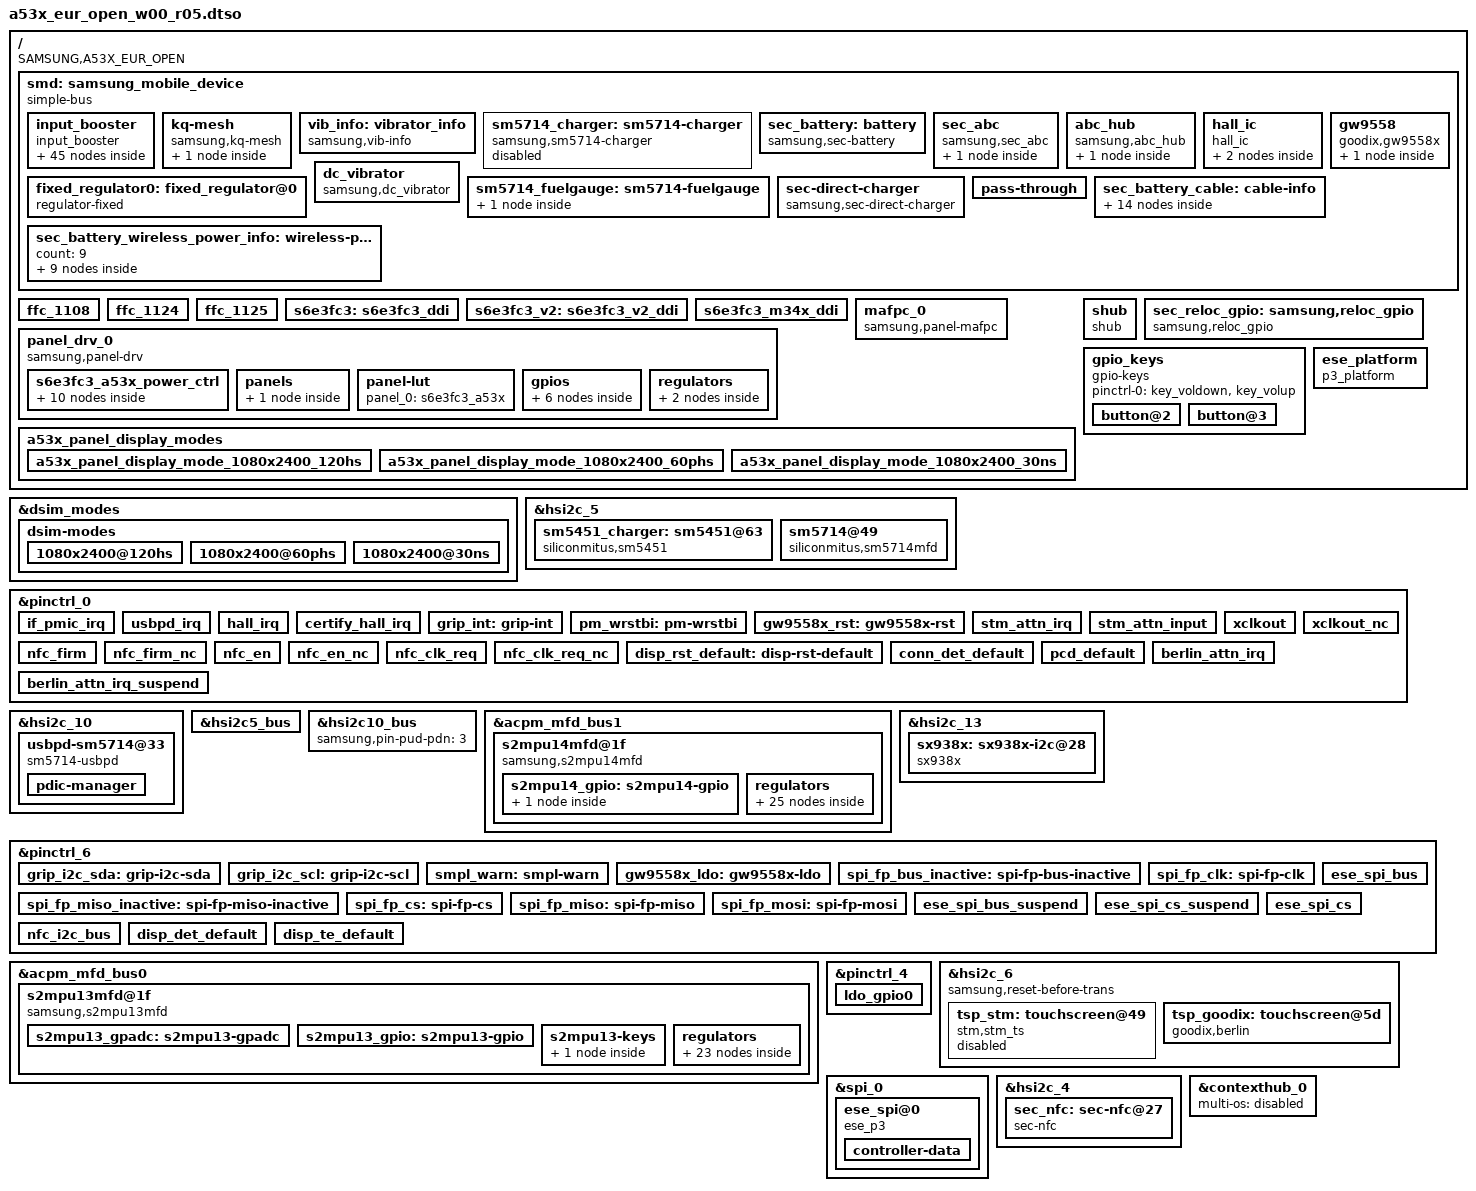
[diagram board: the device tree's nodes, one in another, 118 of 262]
/*
 * Copyright (c) 2018 Samsung Electronics Co., Ltd.
 *              http://www.samsung.com
 *
 * This program is free software; you can redistribute it and/or modify
 * it under the terms of the GNU General Public License version 2 as
 * published by the Free Software Foundation.
*/

/dts-v1/;
/plugin/;

#include <dt-bindings/battery/sec-battery.h>
#include <dt-bindings/clock/s5e8825.h>
#include <dt-bindings/camera/exynos_is_dt.h>
#include <dt-bindings/display/panel-display.h>
#include <dt-bindings/gpio/gpio.h>
#include <dt-bindings/interrupt-controller/s5e8825.h>
#include <dt-bindings/soc/samsung/exynos-cpif.h>
#include <dt-bindings/soc/samsung/exynos-dit.h>

/ {
	fragment@smd {
		target-path = "/";

		__overlay__ {

			smd: samsung_mobile_device {
				compatible = "simple-bus";

				/* #include "../common/input_booster_s5e8825_k66-1.dtsi" */
				/* From input_booster_s5e8825_k66.py */
				/*
				 * Samsung Mobile Input-Booster device tree
				 *
				 * Copyright (c) 2018 Samsung Electronics Co., Ltd.
				 *		http://www.samsung.com
				 *
				 * This program is free software; you can redistribute it and/or modify
				 * it under the terms of the GNU General Public License version 2 as
				 * published by the Free Software Foundation.
				 */
				input_booster {
					status = "okay";
					compatible = "input_booster";
					max_resource_count = "7";
					max_cluster_count = "3";
					#address-cells = <1>;
					#size-cells = <0>;
					/* Each Cpu Cluster Start Cpu */
					cpu_cluster_policy = "7,4,0";
					/* < CLUSTER2, CLUSTER1, CLUSTER0, MIF, INT, HMP, UCC> */
					ib_release_values = "0,0,0,0,0,0,0";
					/* Select Allowed Resource Index Group */
					allowed_resources = "1,3,4";

					booster_key@1 {
						input_booster,label = "key";
						input_booster,type = <0>;
						input_booster,head_time = <0x1f4>;
						input_booster,tail_time = <0>;

						inputbooster,resource {
							compatible = "resource";

							resource@1 {
								resource,label = "cluster1";
								resource,value = <0x177000 0>;
							};

							resource@4 {
								resource,label = "mif";
								resource,value = <0 0>;
							};

							resource@5 {
								resource,label = "int";
								resource,value = <0 0>;
							};
						};
					};

					booster_key@2 {
						input_booster,label = "touchkey";
						input_booster,type = <1>;
						input_booster,head_time = <0>;
						input_booster,tail_time = <0xc8>;

						inputbooster,resource {
							compatible = "resource";

							resource@1 {
								resource,label = "cluster1";
								resource,value = <0x177000 0>;
							};

							resource@4 {
								resource,label = "mif";
								resource,value = <0 0>;
							};

							resource@5 {
								resource,label = "int";
								resource,value = <0 0>;
							};
						};
					};

					booster_key@3 {
						input_booster,label = "touch";
						input_booster,type = <2>;
						input_booster,head_time = <0x82>;
						input_booster,tail_time = <0x1f4>;

						inputbooster,resource {
							compatible = "resource";

							resource@1 {
								resource,label = "cluster1";
								resource,value = <0x119400 0x101d00>;
							};

							resource@4 {
								resource,label = "mif";
								resource,value = <0xf78f0 0xf78f0>;
							};

							resource@5 {
								resource,label = "int";
								resource,value = <0 0>;
							};
						};
					};

					booster_key@4 {
						input_booster,label = "multitouch";
						input_booster,type = <3>;
						input_booster,head_time = <0x3e8>;
						input_booster,tail_time = <0x1f4>;

						inputbooster,resource {
							compatible = "resource";

							resource@1 {
								resource,label = "cluster1";
								resource,value = <0x119400 0x101d00>;
							};

							resource@4 {
								resource,label = "mif";
								resource,value = <0xf78f0 0xf78f0>;
							};

							resource@5 {
								resource,label = "int";
								resource,value = <0 0>;
							};
						};
					};

					booster_key@5 {
						input_booster,label = "keyboard";
						input_booster,type = <4>;
						input_booster,head_time = <0x82>;
						input_booster,tail_time = <0>;

						inputbooster,resource {
							compatible = "resource";

							resource@1 {
								resource,label = "cluster1";
								resource,value = <0x15f900 0x101d00>;
							};

							resource@4 {
								resource,label = "mif";
								resource,value = <0xf78f0 0xf78f0>;
							};

							resource@5 {
								resource,label = "int";
								resource,value = <0 0>;
							};
						};
					};

					booster_key@6 {
						input_booster,label = "mouse";
						input_booster,type = <5>;
						input_booster,head_time = <0x82>;
						input_booster,tail_time = <0x1f4>;

						inputbooster,resource {
							compatible = "resource";

							resource@1 {
								resource,label = "cluster1";
								resource,value = <0x15f900 0x101d00>;
							};

							resource@4 {
								resource,label = "mif";
								resource,value = <0xf78f0 0xf78f0>;
							};

							resource@5 {
								resource,label = "int";
								resource,value = <0 0>;
							};
						};
					};

					booster_key@7 {
						input_booster,label = "mouse_wheel";
						input_booster,type = <6>;
						input_booster,head_time = <0x82>;
						input_booster,tail_time = <0>;

						inputbooster,resource {
							compatible = "resource";

							resource@1 {
								resource,label = "cluster1";
								resource,value = <0x15f900 0>;
							};

							resource@4 {
								resource,label = "mif";
								resource,value = <0xf78f0 0>;
							};

							resource@5 {
								resource,label = "int";
								resource,value = <0 0>;
							};
						};
					};

					booster_key@8 {
						input_booster,label = "pen_hover";
						input_booster,type = <7>;
						input_booster,head_time = <0x82>;
						input_booster,tail_time = <0x1f4>;

						inputbooster,resource {
							compatible = "resource";

							resource@1 {
								resource,label = "cluster1";
								resource,value = <0x15f900 0x101d00>;
							};

							resource@4 {
								resource,label = "mif";
								resource,value = <0 0>;
							};

							resource@5 {
								resource,label = "int";
								resource,value = <0 0>;
							};
						};
					};

					booster_key@9 {
						input_booster,label = "pen";
						input_booster,type = <8>;
						input_booster,head_time = <0xc8>;
						input_booster,tail_time = <0x258>;

						inputbooster,resource {
							compatible = "resource";

							resource@1 {
								resource,label = "cluster1";
								resource,value = <0x1a5e00 0x119400>;
							};

							resource@4 {
								resource,label = "mif";
								resource,value = <0xf78f0 0xf78f0>;
							};

							resource@5 {
								resource,label = "int";
								resource,value = <0 0>;
							};
						};
					};
				};

				/* #include "../nc.dtsi" */
				/* From nc.py */
				/* #include "../kq_mesh.dtsi" */
				/* From kq_mesh.py */
				kq-mesh {
					compatible = "samsung,kq-mesh";
					status = "okay";

					features {
					};
				};

				/* #include "../vibrator_vib_info.dtsi" */
				/* From vibrator_vib_info.py */
				vib_info: vibrator_info {
					status = "okay";
					compatible = "samsung,vib-info";
					functions = "";
					samsung,intensities = <>;
					samsung,haptic_intensities = <>;
				};

				sm5714_charger: sm5714-charger {
					status = "disable";
					compatible = "samsung,sm5714-charger";
				};

				sec_battery: battery {
					battery,otg_name = "sm5714-otg";
					battery,fgsrc_switch_name = "sm5714-fuelgauge"; /* Fuelgauge voltage source */
					/* #include "../battery_common.dtsi" */
					/* From battery_common.py */
					status = "okay";
					compatible = "samsung,sec-battery";
					battery,vendor = "Battery";
					battery,charger_name = "sec-direct-charger";
					battery,fuelgauge_name = "sm5714-fuelgauge";
					battery,technology = <2>; /* POWER_SUPPLY_TECHNOLOGY_LION */
					battery,chip_vendor = "LSI";
					battery,batt_data_version = <1>;
					battery,adc_check_count = <5>;
					battery,temp_check_type = <SEC_BATTERY_TEMP_CHECK_TEMP>;
					battery,usb_temp_check_type = <0>;
					battery,chg_temp_check_type = <SEC_BATTERY_TEMP_CHECK_TEMP>;
					battery,wpc_temp_check_type = <SEC_BATTERY_TEMP_CHECK_NONE>;
					battery,lrp_temp_check_type = <0>;
					battery,thermal_source = <SEC_BATTERY_THERMAL_SOURCE_ADC>;
					battery,usb_thermal_source = <0>;
					battery,chg_thermal_source = <SEC_BATTERY_THERMAL_SOURCE_ADC>;
					battery,wpc_thermal_source = <SEC_BATTERY_THERMAL_SOURCE_NONE>; /* SEC_BATTERY_THERMAL_SOURCE_NONE */
					battery,inbat_ocv_type =  <SEC_BATTERY_OCV_NONE>;
					battery,polling_time = <10 30 30 30 3600>;
					battery,cable_check_type = <SEC_BATTERY_CABLE_CHECK_PSY>;
					battery,cable_source_type = <SEC_BATTERY_CABLE_SOURCE_EXTERNAL>;
					battery,polling_type = <SEC_BATTERY_MONITOR_ALARM>; /* SEC_BATTERY_MONITOR_ALARM */
					battery,monitor_initial_count = <0>;
					battery,battery_check_type = <0>; /* SEC_BATTERY_CHECK_NONE */
					battery,ovp_uvlo_check_type = <SEC_BATTERY_OVP_UVLO_CHGPOLLING>; /* SEC_BATTERY_OVP_UVLO_CHGPOLLING */
					battery,temp_check_count = <1>;
					battery,usb_protection_temp = <610>;
					battery,temp_gap_bat_usb = <200>;
					battery,overheatlimit_threshold = <700>;
					battery,overheatlimit_recovery = <680>;
					battery,wire_warm_overheat_thresh = <500>;
					battery,wire_normal_warm_thresh = <420>;
					battery,wire_cool1_normal_thresh = <180>;
					battery,wire_cool2_cool1_thresh = <150>;
					battery,wire_cool3_cool2_thresh = <50>;
					battery,wire_cold_cool3_thresh = <0>;
					battery,wireless_warm_overheat_thresh = <500>;
					battery,wireless_normal_warm_thresh = <420>;
					battery,wireless_cool1_normal_thresh = <180>;
					battery,wireless_cool2_cool1_thresh = <150>;
					battery,wireless_cool3_cool2_thresh = <50>;
					battery,wireless_cold_cool3_thresh = <0>;
					battery,tx_high_threshold = <500>;
					battery,tx_high_recovery = <450>;
					battery,tx_low_threshold = <0>;
					battery,tx_low_recovery = <50>;
					battery,wire_warm_current = <1735>; /* Less than or equal to 0.72C */
					/* DC 4390 AFC 3150 */
					battery,wire_cool1_current = <0xa8c>; /* Less than or equal to 0.72C */
					battery,wire_cool2_current = <1150>; /* 0.238C */
					battery,wire_cool3_current = <450>; /* 0.1C */
					battery,wireless_warm_current = <1048>; /* 0.24C */
					battery,wireless_cool1_current = <3146>; /* 0.72C */
					battery,wireless_cool2_current = <1048>; /* 0.24C */
					battery,wireless_cool3_current = <437>; /* 0.1C */
					battery,full_check_type = <SEC_BATTERY_FULLCHARGED_FG_CURRENT>;
					battery,full_check_type_2nd = <SEC_BATTERY_FULLCHARGED_FG_CURRENT>;
					battery,full_check_count = <1>;
					battery,chg_gpio_full_check = <0>;
					battery,chg_polarity_full_check = <1>;
					battery,chg_high_temp = <600>;
					battery,chg_high_temp_recovery = <560>;
					battery,chg_input_limit_current = <1000>;
					battery,chg_charging_limit_current = <1400>;
					/* 45w pwr on, 45w pwr off, 25w pwr on, 25w pwr off */
					battery,dchg_high_temp = <0x258>;
					battery,dchg_high_temp_recovery = <0x230>;
					battery,dchg_high_batt_temp = <0x190>; /* DISABLED */
					battery,dchg_high_batt_temp_recovery = <0x17c>; /* DISABLED */
					battery,dchg_input_limit_current = <1000>;
					battery,dchg_charging_limit_current = <2000>;
					battery,wpc_temp_control_source = <1>;
					battery,wpc_high_temp = <400>;
					battery,wpc_high_temp_recovery = <380>;
					battery,wpc_input_limit_current = <800>;
					battery,wpc_charging_limit_current = <1000>;
					battery,wpc_temp_lcd_on_control_source = <1>;
					battery,wpc_lcd_on_input_limit_current = <800>;
					battery,wpc_store_high_temp = <360>;
					battery,wpc_store_high_temp_recovery = <340>;
					battery,wpc_store_charging_limit_current = <400>;
					battery,wpc_store_lcd_on_high_temp = <360>;
					battery,wpc_store_lcd_on_high_temp_rec = <300>;
					battery,wpc_store_lcd_on_charging_limit_current = <400>;
					battery,fcc_by_tx = <1200>;
					battery,sleep_mode_limit_current = <800>;
					battery,wc_full_input_limit_current = <100>;
					battery,ta_alert_wa;
					battery,mix_high_temp = <420>;
					battery,mix_high_chg_temp = <500>;
					battery,mix_high_temp_recovery = <390>;
					/* battery,usb_conn_slope_avg = <9>; */
					/* battery,enable_mix_v2; */
					/* if you want to use mix_v2 concept, add "battery,enable_mix_v2;" */
					battery,mix_v2_lrp_recov = <460>;
					battery,mix_v2_lrp_cond = <480>;
					battery,mix_v2_bat_cond = <480>;
					battery,mix_v2_chg_cond = <0>; /* 0 means no use chg thm condition */
					battery,mix_v2_dchg_cond = <0>; /* 0 means no use dchg thm condition */
					battery,full_condition_type = <(SEC_BATTERY_FULL_CONDITION_NOTIMEFULL | SEC_BATTERY_FULL_CONDITION_VCELL)>;
					battery,full_condition_soc = <93>;
					/* battery,full_condition_vcell = FV - 50mV set when variable is parsed */
					battery,recharge_check_count = <1>;
					battery,recharge_condition_type = <SEC_BATTERY_RECHARGE_CONDITION_VCELL>;
					battery,recharge_condition_soc = <98>;
					/* battery,recharge_condition_vcell = FV - 70mV set when variable is parsed */
					battery,charging_reset_time = <0>;
					battery,chg_float_voltage = <0x1144>;
					battery,pre_afc_work_delay = <2000>;
					battery,pre_wc_afc_work_delay = <4000>;
					battery,pre_afc_input_current = <500>;
					battery,pre_wc_afc_input_current = <500>;
					battery,swelling_high_rechg_voltage = <4050>;
					/*battery,swelling_low_rechg_voltage = FV - 150mA set when variable is parsed */
					battery,siop_icl = <1200>;
					battery,siop_fcc = <1800>;
					battery,siop_hv_icl = <675>;
					battery,siop_hv_icl_2nd = <550>;
					battery,siop_hv_fcc = <1800>;
					battery,siop_apdo_icl = <1000>;
					battery,siop_apdo_fcc = <2000>;
					battery,siop_wpc_icl = <600>;
					battery,siop_wpc_fcc = <1000 500 100>; /* siop_level 70 10 0 */
					battery,siop_hv_wpc_icl = <700>;
					battery,siop_hv_wpc_fcc = <1000 500 100>; /* siop_level 70 10 0 */
					battery,siop_store_hv_wpc_icl = <450>;
					battery,store_mode_buckoff;
					/* trig, recov */
					battery,temp_table_LRP_45W = <385 365>;
					battery,rp_current_rp1 = <500>;
					battery,rp_current_rp2 = <1500>;
					battery,rp_current_rp3 = <3000>;
					battery,rp_current_rdu_rp3 = <2100>;
					battery,rp_current_abnormal_rp3 = <1800>;
					battery,pd_charging_charge_power = <15000>;
					battery,max_charging_current = <0xa8c>;
					battery,store_mode_charging_max = <70>;
					battery,store_mode_charging_min = <60>;
					battery,wireless_cc_cv = <85>;
					battery,wireless_otg_input_current = <900>;
					battery,age_data_cycle = <0 0x12c 0x190 0x2bc 0x3e8>;
					battery,age_data_full_condition_soc = <93 92 91 90 89>;
					battery,age_data_common_offset = <0 0x14 0x28 0x6e>;
					/* battery,age_data_max_charging_current_offset = <0 100 200 300 400>; */
					/* cycle, chg_float_voltage, recharge_condition_vcell, full_condition_vcell, full_condition_soc, step charging condition */
					battery,age_data = <0 0x1144 0x10fe 0x1112 0x5d 0x12c 0x1130 0x10ea 0x10fe 0x5c 0x190 0x111c 0x10d6 0x10ea 0x5b 0x2bc 0x1108 0x10c2 0x10d6 0x5a 0x3e8 0x10d6 0x1090 0x10a4 0x59>;
					battery,health_condition_cycle = <900 1200 1500>;
					battery,health_condition_asoc = <0 0 0>; /* Default ASOC Disabled */
					battery,max_input_voltage = <9000>; /* mV */
					battery,max_input_current = <3000>; /* mA */
					battery,cisd_alg_index = <8>;
					battery,cisd_max_voltage_thr = <5000>; /* batttery ovp dettection voltage */
					battery,ignore_cisd_index = <0 0>;
					battery,ignore_cisd_index_d = <0 80>; /* Do not use BUCK_OFF_PER_DAY, DROP_SENSOR_PER_DAY */
					battery,expired_time = <9900>; /* 95 + 60 minutes = 155 */
					battery,recharging_expired_time = <5400>; /* 90 minutes */
					battery,battery_full_capacity = <5000>;
					battery,ttf_capacity = <4390>;
					battery,cv_data = <0xd27 0x352 0x690 0xbed 0x35c 0x5ef 0xaf2 0x366 0x5bc 0x9ca 0x370 0x576 0x844 0x37a 0x52f 0x816 0x384 0x4d4 0x735 0x38e 0x470 0x727 0x398 0x40b 0x704 0x3a2 0x39c 0x68c 0x3ac 0x33e 0x5f9 0x3b6 0x2c5 0x566 0x3c0 0x24c 0x410 0x3ca 0x1d4 0x3bd 0x3d4 0x120 0x340 0x3de 0x6b 0x2c9 0x3e8 0>;
					io-channels = <&s2mpu13_gpadc 2 &s2mpu13_gpadc 3>;
					io-channel-names = "adc-temp", "adc-chg-temp", "n/a", "n/a", "n/a";
					/* /home/dpi/qb5_8814/workspace/P4_1716/kernel/kmodule/battery/suwon/common/dts/a26xs/battery_common.dtsi */
					pinctrl-names = "default";
					battery,dchg_temp_check_type = <SEC_BATTERY_TEMP_CHECK_TEMP>;
					battery,dchg_thermal_source = <SEC_BATTERY_THERMAL_SOURCE_ADC>;
					battery,dctp_by_cgtp;
					battery,temp_table_adc = <0x133 0x168 0x1a5 0x1f8 0x23e 0x29e 0x2f9 0x37c 0x418 0x4c0 0x575 0x652 0x714 0x7f3 0x8d8 0x9b9 0xa9a 0xb6c 0xc32 0xce1 0xd85 0xe0d 0xe83>;
					battery,temp_table_data = <
						900 850 800 750 700 650 600 550 500 450
						400 350 300 250 200 150 100 50 0 (-50)
						(-100) (-150) (-200)
						>;
					battery,chg_temp_table_adc = <0x125 0x15d 0x198 0x1e6 0x22d 0x28d 0x2d7 0x360 0x3ff 0x49c 0x558 0x623 0x6e6 0x78e 0x8b4 0x975 0xa4b 0xac2 0xbd3 0xc7f 0xd4f 0xdee 0xe65>;
					battery,chg_temp_table_data = <
						900 850 800 750 700 650 600 550 500 450
						400 350 300 250 200 150 100 50 0 (-50)
						(-100) (-150) (-200)
						>;
					battery,full_condition_vcell = <0x1112>;
					battery,recharge_condition_vcell = <0x10fe>;
					battery,high_temp_float = <4200>;
					battery,low_temp_float = <0x1144>;
					battery,swelling_low_rechg_voltage = <0x10ae>;
					battery,chg_ocp_current = <0>;
					battery,max_charging_charge_power = <25000>; /* 25W */
					/* step charging option */
					battery,step_chg_type = <0>;
					/* direct step charging option */
					battery,dc_step_chg_type = <0xE9>;
					battery,dc_step_chg_charge_power = <22000>;
					battery,dc_step_chg_step = <3>;
					battery,dc_step_chg_cond_vol = <0xfd2 0x109a 0x1144>; /*<25w 3step> STEP_CHARGING_CONDITION_VOLTAGE */
					battery,dc_step_chg_val_vfloat = <0xfd2 0x109a 0x1144>; /* <25w 3step> STEP_CHARGING_CONDITION_FLOAT_VOLTAGE */
					battery,dc_step_chg_val_iout = <0x12c0 0xfd2 0xe10>; /* <25w 3step> */
					battery,dc_step_chg_iin_check_cnt = <3>;
					battery,dc_step_chg_cond_soc = <0x19 0x41 0x64>; /* <25w 3step> STEP_CHARGING_CONDITION_SOC */
					battery,standard_curr = <0xe10>;
					battery,ttf_hv_charge_current = <2450>;
					battery,ttf_dc25_charge_current = <3800>;
					battery,support_vpdo;
					battery,d2d_check_type = <2>;
				};

				/* #include "../abc_spec_manager_type1.dtsi" */
				/* From abc_spec_manager_type1.py */
				sec_abc {
					compatible = "samsung,sec_abc";
					status = "okay";

					abc_spec_type1 {
						module_list = "gpu", "gpu_qc", "gpu_qc", "camera", "camera", "vib";
						name_list = "gpu_fault", "gpu_fault", "gpu_page_fault", "mipi_overflow", "i2c_fail", "int_gnd_short";
						threshold_cnt = <20>, <2>, <20>, <1>, <1>, <25>;
						threshold_time = <1200>, <1200>, <1200>, <0>, <0>, <5>;
					};
				};

				/* #include "../ap_slsi_s5e8825.dtsi" */
				/* From ap_slsi_s5e8825.py */
				/* #include "../abc_common.dtsi" */
				/* From abc_common.py */
				abc_hub {
					compatible = "samsung,abc_hub";
					status = "okay";

					bootc {
						bootc,time_spec_user = <100000>; /* user binary user build */
						bootc,time_spec_eng = <150000>; /* user binary eng build */
						bootc,time_spec_fac = <100000>; /* factory binary */
					};
				};

				hall_ic: hall_ic {
					status = "okay";
					compatible = "hall_ic";
					pinctrl-names = "default";
					pinctrl-0 = <&hall_irq &certify_hall_irq>;
					hall_ic,debounce-interval = <0x32>;

					hall: hall {
						event = <0x15>;
						gpios = <&gpa0 1 1>;
					};

					certify_hall: certify_hall {
						event = <0x1b>;
						gpios = <&gpa0 0 1>;
					};
				};

				gw9558 {
					compatible = "goodix,gw9558x";
					reg = <0>;
					spi-max-frequency = <0x17d7840>;
					clocks = <&clock 0x4c3 &clock 0x4d5>;
					clock-names = "gate_spi_clk", "ipclk_spi";
					pinctrl-names = "default", "pins_poweron", "pins_poweroff";
					pinctrl-0 = <&gw9558x_ldo &gw9558x_rst>;
					pinctrl-1 = <&spi_fp_clk &spi_fp_cs &spi_fp_miso &spi_fp_mosi>;
					pinctrl-2 = <&spi_fp_bus_inactive &spi_fp_miso_inactive>;
					gpio-controller;
					#gpio-cells = <2>;
					goodix,gpio_pwr = <&gpp3 4 0>;
					goodix,gpio_reset = <&gpc3 0 0>;
					goodix,chip_id = "GW9558";
					goodix,position = "11.81,0.00,9.10,9.10,14.80,14.80,12.00,12.00,5.00";
					goodix,modelinfo = "A536";
					goodix,rb = "800,235,-1,D8D8D8,8C8C8C";

					controller-data {
						cs-gpio = <&gpp0 7 0>;
						samsung,spi-feedback-delay = <0>;
						samsung,spi-chip-select-mode = <0>;
					};
				};

				fixed_regulator0: fixed_regulator@0 {
					compatible = "regulator-fixed";
					regulator-name = "fixed_regulator0";
					gpio = <&gpf1 0 0>;
					pinctrl-names = "default";
					pinctrl-0 = <&ldo_gpio0>;
					enable-active-high;
				};

				/* #include "../dc_vibrator.dtsi" */
				/* From dc_vibrator.py */
				dc_vibrator {
					compatible = "samsung,dc_vibrator";
					status = "okay";
					dc_vib,motor_type = "COINDC";
					dc_vib,regulator_name = "dc_vib";
					dc_vib-supply = <&s_l21_reg>;
				};

				/*
				 * sm5714 battery device tree common
				 *
				 * Copyright (c) 2021 Samsung Electronics Co., Ltd.
				 *		http://www.samsung.com
				 *
				 * This program is free software; you can redistribute it and/or modify
				 * it under the terms of the GNU General Public License version 2 as
				 * published by the Free Software Foundation.
				 */
				sm5714_fuelgauge: sm5714-fuelgauge {
					/* /home/dpi/qb5_8814/workspace/P4_1716/android/kernel/kmodule/battery/suwon/fuelgauge/sm5714/sm5714_fuelgauge.a53x.dtsi */
					/*
					 * A53x battery device tree common
					 *
					 * Copyright (c) 2021 Samsung Electronics Co., Ltd.
					 *		http://www.samsung.com
					 *
					 * This program is free software; you can redistribute it and/or modify
					 * it under the terms of the GNU General Public License version 2 as
					 * published by the Free Software Foundation.
					 */
					status = "okay";
					fuelgauge,fuel_alert_soc = <1>;
					fuelgauge,capacity_max = <1000>;
					fuelgauge,capacity_max_margin = <300>;
					fuelgauge,capacity_min = <0>;
					fuelgauge,capacity_calculation_type = <0x1F>;
					fuelgauge,using_temp_compensation;
					fuelgauge,low_temp_limit = <100>;
					fuelgauge,using_hw_vempty;
					fuelgauge,sw_v_empty_voltage = <3200>;
					fuelgauge,sw_v_empty_voltage_cisd = <3100>;
					fuelgauge,sw_v_empty_recover_voltage = <3480>;
					fuelgauge,capacity = <5000>;
					fuelgauge,bat_id_gpio = <
					&s2mpu14_gpio 8 0 /* BAT_ID_2 */
					&s2mpu14_gpio 7 0 /* BAT_ID_1 */
					>;

					battery_params {
						battery,id = <3>; /* default ID */
						/*
						 * BAT_ID_1/BAT_ID_2
						 * 11: ATL, 10: LGES
						 * 01: SDI, 00: BYD(TBD)
						 */
						/* 11 : ATL battery data */
						battery3,battery_type = <4420 0x2501>; /* batt_v_max, cap */
						battery3,battery_table0 = <
							0x1400 0x1B3F 0x1C19 0x1CE4 0x1D61 0x1D7B 0x1D89 0x1D93
							0x1DBE 0x1DEE 0x1E42 0x1E5E 0x1E8D 0x1EB7 0x1F0E 0x1F40
							0x1F8D 0x200B 0x206A 0x20D4 0x2146 0x21FD 0x2305 0x2400
							>;
						battery3,battery_table1 = <
							0x0000 0x0099 0x0199 0x0319 0x0499 0x0599 0x0799 0x0B33
							0x0E33 0x1233 0x1C4C 0x2166 0x28E6 0x2E00 0x3599 0x3819
							0x3A99 0x4233 0x4733 0x4C4C 0x514C 0x58E6 0x6400 0x6419
							>;
						battery3,battery_table2 = <
							0x444B 0x3E40 0x3B3C 0x3738 0x3435 0x3334 0x3333 0x3233
							0x444B 0x3E40 0x3B3C 0x3738 0x3435 0x3334 0x3333 0x3233
							>;
						/*spare min max factor chg_factor dischg_factor manvalue*/
						battery3,rs_value = <0x48 0x48 0x3800 0x10A 0x599 0x599 0x50>;
						battery3,v_alarm = <3100 200>;
						battery3,topoff = <750>;
						battery3,i_cal = <1 0x0 0x0800 0x0800 0 0x0 0x0800 0x0825>;
						battery3,v_cal = <1 0 0 0 0 0x18 0>;
						battery3,temp_std = <25>;
						battery3,tem_poff = <3400 50 3250 50>;
						battery3,aux_ctrl = <0x322 0x5800>;
						battery3,data_ver = <4>;
						battery3,v_max_table = <0x2305 0x22DF 0x22B8 0x2290 0x222F>;
						battery3,q_max_table = <0x2501 0x2463 0x23C4 0x2326 0x219A>;
						/* 01 : SDI battery data */
						battery1,battery_type = <4420 0x24ED>; /* batt_v_max, cap */
						battery1,battery_table0 = <
							0x1400 0x1B41 0x1C27 0x1CD8 0x1D30 0x1D6B 0x1D7B 0x1D8E
							0x1DE3 0x1E0B 0x1E51 0x1E70 0x1EAA 0x1EDD 0x1F1E 0x1F4C
							0x1F97 0x1FFD 0x205F 0x20C8 0x213B 0x21F2 0x22FA 0x2400
							>;
						battery1,battery_table1 = <
							0x0000 0x0080 0x0199 0x0319 0x0433 0x0533 0x064C 0x0B80
							0x1233 0x1766 0x1F4C 0x2480 0x2C4C 0x3180 0x36B3 0x394C
							0x3BE6 0x4119 0x464C 0x4B80 0x50B3 0x5880 0x6400 0x6419
							>;
						battery1,battery_table2 = <
							0x444B 0x3E40 0x3B3C 0x3738 0x3435 0x3334 0x3333 0x3233
							0x444B 0x3E40 0x3B3C 0x3738 0x3435 0x3334 0x3333 0x3233
							>;
						/*spare min max factor chg_factor dischg_factor manvalue*/
						battery1,rs_value = <0x48 0x48 0x3800 0x10A 0x599 0x599 0x50>;
						battery1,v_alarm = <3100 200>;
						battery1,topoff = <750>;
						battery1,i_cal = <1 0x0 0x0800 0x0800 0 0x0 0x0800 0x0825>;
						battery1,v_cal = <1 0 0 0 0 0x18 0>;
						battery1,temp_std = <25>;
						battery1,tem_poff = <3400 50 3250 50>;
						battery1,aux_ctrl = <0x322 0x5800>;
						battery1,data_ver = <2>;
						battery1,v_max_table = <0x22FA 0x22D4 0x22AD 0x2286 0x2225>;
						battery1,q_max_table = <0x24ED 0x2449 0x23A3 0x22FF 0x2163>;
						/* 02 : LGES battery data */
						battery2,battery_type = <4420 0x23FD>; /* batt_v_max, cap */
						battery2,battery_table0 = <
							0x1400 0x1B56 0x1C21 0x1D02 0x1D48 0x1D73 0x1D8A 0x1D92
							0x1DB7 0x1DF2 0x1E4D 0x1E6C 0x1EA5 0x1ED6 0x1F14 0x1F47
							0x1F8D 0x1FD5 0x2030 0x20D5 0x2151 0x21D4 0x22E7 0x2400
							>;
						battery2,battery_table1 = <
							0x0000 0x0099 0x01B3 0x03CC 0x04E6 0x0600 0x09CC 0x0C80
							0x0F33 0x1499 0x1F66 0x24CC 0x2CE6 0x324C 0x37B3 0x3A66
							0x3D19 0x3FCC 0x4533 0x4D4C 0x52B3 0x5819 0x6400 0x6419
							>;
						battery2,battery_table2 = <
							0x444B 0x3E40 0x3B3C 0x3738 0x3435 0x3334 0x3333 0x3233
							0x444B 0x3E40 0x3B3C 0x3738 0x3435 0x3334 0x3333 0x3233
							>;
						/*spare min max factor chg_factor dischg_factor manvalue*/
						battery2,rs_value = <0x48 0x48 0x3800 0x10A 0x599 0x599 0x50>;
						battery2,v_alarm = <3100 200>;
						battery2,topoff = <750>;
						battery2,i_cal = <1 0x0 0x0800 0x0800 0 0x0  0x0808 0x0825>;
						battery2,v_cal = <1 0 0 1 0 0 0>;
						battery2,temp_std = <25>;
						battery2,tem_poff = <3400 50 3250 50>;
						battery2,aux_ctrl = <0x322 0x5800>;
						battery2,data_ver = <2>;
						battery2,v_max_table = <0x22E7 0x22C0 0x229A 0x2274 0x2214>;
						battery2,q_max_table = <0x23FD 0x2344 0x228C 0x21D4 0x2063>;
						/* 00 : BYD battery data */
						battery0,battery_type = <4420 0x24B3>; /* batt_v_max, cap */
						battery0,battery_table0 = <
							0x1400 0x1B21 0x1BFE 0x1CCD 0x1D51 0x1D79 0x1D86 0x1D96
							0x1DBB 0x1DF4 0x1E06 0x1E4E 0x1E93 0x1EF8 0x1F40 0x1F77
							0x1FC6 0x1FF9 0x205C 0x20C8 0x213E 0x21FB 0x2306 0x2400
							>;
						battery0,battery_table1 = <
							0x0000 0x0080 0x0180 0x0319 0x04B3 0x05B3 0x074C 0x0C19
							0x0EB3 0x1400 0x1699 0x1E80 0x2900 0x3399 0x38CC 0x3B80
							0x3E19 0x40B3 0x4600 0x4B4C 0x5080 0x5866 0x6400 0x6419
							>;
						battery0,battery_table2 = <
							0x444B 0x3E40 0x3B3C 0x3738 0x3435 0x3334 0x3333 0x3233
							0x444B 0x3E40 0x3B3C 0x3738 0x3435 0x3334 0x3333 0x3233
							>;
						/*spare min max factor chg_factor dischg_factor manvalue*/
						battery0,rs_value = <0x48 0x48 0x3800 0x10A 0x599 0x599 0x50>;
						battery0,v_alarm = <3100 200>;
						battery0,topoff = <750>;
						battery0,i_cal = <1 0x0 0x0800 0x0800 0 0x0  0x0800 0x0825>;
						battery0,v_cal = <1 0 0 0 0 0x18 0>;
						battery0,temp_std = <25>;
						battery0,tem_poff = <3400 50 3250 50>;
						battery0,aux_ctrl = <0x322 0x5800>;
						battery0,data_ver = <2>;
						battery0,v_max_table = <0x2306 0x22DE 0x22B7 0x228F 0x222C>;
						battery0,q_max_table = <0x24B3 0x240E 0x2369 0x2326 0x212A>;
					};
				};

				/* #include "../sec_direct_charger.dtsi" */
				/* From sec_direct_charger.py */
				sec-direct-charger {
					status = "okay";
					compatible = "samsung,sec-direct-charger";
					charger,battery_name = "battery";
					charger,main_charger = "sm5714-charger";
					charger,direct_charger = "sm5451-charger";
					charger,dchg_min_current = <2000>;
					charger,ta_alert_wa;
				};

				/* /home/dpi/qb5_8814/workspace/P4_1716/kernel/kmodule/battery/suwon/common/sec_direct_charger/dts/a26xs/sec_direct_charger.dtsi */
				pass-through {
					start_delay = <5000>; /* msec */
					init_delay = <5000>; /* msec */
					min_cap = <200>; /* 0.1 % */
					fixed_sc_cap = <900>; /* 0.1 % */
					max_icl = <3000>; /* mA */
					vfloat = <0x1144>;
				};

				/* sec_battery_cable
				 *   0	UNKNOWN,
				 *   1	NONE,
				 *   2	PREPARE_TA,
				 *   3	TA,
				 *   4	USB,
				 *   5	USB_CDP,
				 *   6	9V_TA,
				 *   7	9V_ERR,
				 *   8	9V_UNKNOWN,
				 *   9	12V_TA,
				 *  10	WIRELESS,
				 *  11	HV_WIRELESS,
				 *  12	PMA_WIRELESS,
				 *  13	WIRELESS_PACK,
				 *  14	CABLE_WIRELESS_HV_PACK,
				 *  15	WIRELESS_STAND,
				 *  16	WIRELESS_HV_STAND,
				 *  17	QC20,
				 *  18	QC30,
				 *  19	PDIC,
				 *  20	UARTOFF,
				 *  21	OTG,
				 *  22	LAN_HUB,
				 *  23	POWER_SHARING,
				 *  24	HMT_CONNECTED,
				 *  25	HMT_CHARGE,
				 *  26	HV_TA_CHG_LIMIT,
				 *  27	WIRELESS_VEHICLE,
				 *  28	WIRELESS_HV_VEHICLE,
				 *  29	PREPARE_WIRELESS_HV,
				 *  30  TIMEOUT,
				 *  31  SMART_OTG,
				 *  32  SMART_NOTG,
				 *  33  WIRELESS_TX,
				 *  34	HV_WIRELESS_20,
				 *  35	HV_WIRELESS_20_LIMIT,
				 *  36	WIRELESS_FAKE,
				 *  37  PREPARE_WIRELESS_20,
				 *  38	CABLE_PDIC_APDO,
				 *  39  CABLE_POGO,
				 *  40  CABLE_POGO_9V,
				 *  41  FPDO_DC,
				 *  42	CABLE_MAX,
				 */
				sec_battery_cable: cable-info {
					default_input_current = <1800>;
					default_charging_current = <2100>;
					full_check_current_1st = <750>;
					full_check_current_2nd = <250>;

					current_group_1 {
						cable_number = <
							SEC_BATTERY_CABLE_PREPARE_TA
							SEC_BATTERY_CABLE_PDIC
							SEC_BATTERY_CABLE_OTG
							SEC_BATTERY_CABLE_LAN_HUB
							SEC_BATTERY_CABLE_POWER_SHARING>;
						input_current = <500>;
						charging_current = <500>;
					};

					current_group_2 {
						cable_number = <
							SEC_BATTERY_CABLE_HMT_CHARGE
							SEC_BATTERY_CABLE_SMART_OTG>;
						input_current = <1000>;
						charging_current = <1000>;
					};

					current_group_3 {
						cable_number = <
							SEC_BATTERY_CABLE_USB_CDP
							SEC_BATTERY_CABLE_SMART_NOTG>;
						input_current = <1500>;
						charging_current = <1500>;
					};

					current_group_4 {
						cable_number = <SEC_BATTERY_CABLE_9V_TA SEC_BATTERY_CABLE_9V_ERR
							SEC_BATTERY_CABLE_9V_UNKNOWN SEC_BATTERY_CABLE_QC20 SEC_BATTERY_CABLE_QC30>;
						input_current = <1650>;
						/*
						 * cable_number = <SEC_BATTERY_CABLE_9V_TA SEC_BATTERY_CABLE_9V_ERR
						 * SEC_BATTERY_CABLE_9V_UNKNOWN SEC_BATTERY_CABLE_QC20 SEC_BATTERY_CABLE_QC30>;
						 */
						charging_current = <0xa8c>;
					};

					current_group_5 {
						cable_number = <SEC_BATTERY_CABLE_12V_TA>;
						input_current = <1650>;
						/* cable_number = <SEC_BATTERY_CABLE_12V_TA>; */
						charging_current = <0xa8c>;
					};

					current_group_6 {
						cable_number = <
							SEC_BATTERY_CABLE_WIRELESS
							SEC_BATTERY_CABLE_PMA_WIRELESS
							SEC_BATTERY_CABLE_WIRELESS_STAND
							SEC_BATTERY_CABLE_WIRELESS_VEHICLE
							SEC_BATTERY_CABLE_WIRELESS_FAKE>;
						input_current = <800>;
						charging_current = <2350>;
					};

					current_group_7 {
						cable_number = <SEC_BATTERY_CABLE_WIRELESS_PACK>;
						input_current = <700>;
						charging_current = <2350>;
					};

					current_group_8 {
						cable_number = <SEC_BATTERY_CABLE_HMT_CONNECTED>;
						input_current = <1000>;
						charging_current = <450>;
					};

					current_group_9 {
						cable_number = <SEC_BATTERY_CABLE_HV_TA_CHG_LIMIT>;
						input_current = <1800>;
						charging_current = <1800>;
					};

					current_group_10 {
						cable_number = <
							SEC_BATTERY_CABLE_HV_WIRELESS
							SEC_BATTERY_CABLE_WIRELESS_HV_PACK
							SEC_BATTERY_CABLE_WIRELESS_HV_STAND
							SEC_BATTERY_CABLE_WIRELESS_HV_VEHICLE
							SEC_BATTERY_CABLE_HV_WIRELESS_20_LIMIT>;
						input_current = <650>;
						charging_current = <2350>;
					};

					current_group_11 {
						cable_number = <
							SEC_BATTERY_CABLE_PREPARE_WIRELESS_HV
							SEC_BATTERY_CABLE_PREPARE_WIRELESS_20>;
						input_current = <500>;
						charging_current = <1200>;
					};

					current_group_12 {
						cable_number = <
							SEC_BATTERY_CABLE_NONE
							SEC_BATTERY_CABLE_USB
							SEC_BATTERY_CABLE_TIMEOUT>;
						input_current = <475>;
						charging_current = <550>;
					};

					current_group_13 {
						cable_number = <SEC_BATTERY_CABLE_HV_WIRELESS_20>;
						input_current = <1200>;
						charging_current = <2350>;
					};

					current_group_14 {
						cable_number = <SEC_BATTERY_CABLE_WIRELESS_TX>;
						input_current = <800>;
						charging_current = <2350>;
					};
				};

				sec_battery_wireless_power_info: wireless-power-info {
					count = <9>;

					current_group_0 {
						wireless_power_class = <2>;
						vout = <9000>;
						input_current_limit = <830>;
						fast_charging_current = <3150>;
						ttf_charge_current = <1500>;
						rx_power = <7500>;
					};

					current_group_1 {
						wireless_power_class = <2>;
						vout = <10000>;
						input_current_limit = <750>;
						fast_charging_current = <3150>;
						ttf_charge_current = <1500>;
						rx_power = <7500>;
					};

					current_group_2 {
						wireless_power_class = <2>;
						vout = <11000>;
						input_current_limit = <680>;
						fast_charging_current = <3150>;
						ttf_charge_current = <1500>;
						rx_power = <7500>;
					};

					current_group_3 {
						wireless_power_class = <2>;
						vout = <12000>;
						input_current_limit = <625>;
						fast_charging_current = <3150>;
						ttf_charge_current = <1500>;
						rx_power = <7500>;
					};

					current_group_4 {
						wireless_power_class = <2>;
						vout = <9000>;
						input_current_limit = <1330>;
						fast_charging_current = <3150>;
						ttf_charge_current = <2175>;
						rx_power = <12000>;
					};

					current_group_5 {
						wireless_power_class = <2>;
						vout = <11000>;
						input_current_limit = <1090>;
						fast_charging_current = <3150>;
						ttf_charge_current = <2100>;
						rx_power = <12000>;
					};

					current_group_6 {
						wireless_power_class = <2>;
						vout = <12000>;
						input_current_limit = <1000>;
						fast_charging_current = <3150>;
						ttf_charge_current = <2100>;
						rx_power = <12000>;
					};

					current_group_7 {
						wireless_power_class = <2>;
						vout = <11000>;
						input_current_limit = <1360>;
						fast_charging_current = <3150>;
						ttf_charge_current = <2300>;
						rx_power = <15000>;
					};

					current_group_8 {
						wireless_power_class = <2>;
						vout = <12000>;
						input_current_limit = <1250>;
						fast_charging_current = <3150>;
						ttf_charge_current = <2300>;
						rx_power = <15000>;
					};
				};
			};
		};
	};
};

#include "../display_s6e3fc3_a53x_adaptive_mipi.dtsi"

/ {
	fragment@panel_drv {
		target-path = "/";

		__overlay__ {

			ffc_1108: ffc_1108 {
				osc = <0x2c434>;
				hs-clk = <0x454>;
				command = [c5 0d 10 80 45 53 c7];
			};

			ffc_1124: ffc_1124 {
				osc = <0x2c434>;
				hs-clk = <0x464>;
				command = [c5 0d 10 80 45 52 96];
			};

			ffc_1125: ffc_1125 {
				osc = <0x2c434>;
				hs-clk = <0x465>;
				command = [c5 0d 10 80 45 52 83];
			};

			s6e3fc3: s6e3fc3_ddi {
				id = <0x1083>;
				mode = <2>;
				resolution = <0x438 0x960>;
				size = <0x43 0x96>;
				timing,refresh = <0x3c>;
				timing,h-porch = <2 2 2>;
				timing,v-porch = <0xf 8 1>;
				timing,dsi-hs-clk = <0x454>;
				timing,pmsk = <2 0xaa 2 0x7627 0xd 4 0 0 0 0 0 0 0 0>;
				timing,dsi-escape-clk = <0x14>;
				mic_en = <0>;
				mic_ratio = <2>;
				mic_ver = <2>;
				type_of_ddi = <0>;
				dsc_en = <1>;
				dsc_cnt = <1>;
				dsc_slice_num = <2>;
				dsc_slice_h = <0x28>;
				data_lane = <4>;
				cmd_underrun_cnt = <0x26cf>;
				mres_en = <1>;
				mres_number = <1>;
				mres_width = <0x438>;
				mres_height = <0x960>;
				mres_dsc_width = <0x21c>;
				mres_dsc_height = <0x28>;
				mres_dsc_en = <1>;
				default_mode = <1>;
				display_mode = <0x438 0x960 0x78 0x83b 1 0x21c 0x28 0x438 0x960 0x3c 0x1f37 1 0x21c 0x28>;
				hdr_num = <0>;
				color_mode = <0 7 9>;
				dynamic_mipi_tbl = <&dsim_freq_1108 &dsim_freq_1124 &dsim_freq_1125>;
				dynamic_mipi_ffc0 = <&ffc_1108 &ffc_1124 &ffc_1125>;
			};

			s6e3fc3_v2: s6e3fc3_v2_ddi {
				id = <0x800004>;
				mode = <2>;
				resolution = <0x438 0x960>;
				size = <0x46 0x9b>;
				timing,refresh = <0x3c>;
				timing,h-porch = <2 2 2>;
				timing,v-porch = <0xf 8 1>;
				timing,dsi-hs-clk = <0x67c>;
				timing,pmsk = <4 0xff 1 0 0xd 4 0 0 0 0 0 0 0 0>;
				timing,dsi-escape-clk = <0x14>;
				mic_en = <0>;
				mic_ratio = <0>;
				mic_ver = <0>;
				type_of_ddi = <0>;
				dsc_en = <1>;
				dsc_cnt = <1>;
				dsc_slice_num = <2>;
				dsc_slice_h = <0x28>;
				data_lane = <4>;
				cmd_underrun_cnt = <0x26cf>;
				mres_en = <1>;
				mres_number = <1>;
				mres_width = <0x438>;
				mres_height = <0x960>;
				mres_dsc_width = <0x21c>;
				mres_dsc_height = <0x28>;
				mres_dsc_en = <1>;
				default_mode = <1>;
				display_mode = <0x438 0x960 0x5a 0x13e5 1 0x21c 0x28 0x438 0x960 0x3c 0x26cf 1 0x21c 0x28>;
				hdr_num = <0>;
			};

			s6e3fc3_m34x_ddi: s6e3fc3_m34x_ddi {
				size = <0x46 0x95>;
				hdr_num = <0>;
			};

			mafpc_0: mafpc_0 {
				compatible = "samsung,panel-mafpc";
				status = "okay";
			};

			panel_drv_0: panel_drv_0 {
				status = "okay";
				compatible = "samsung,panel-drv";
				panel,id = <0>;
				pinctrl-names = "default";
				pinctrl-0 = <&disp_rst_default &disp_det_default &conn_det_default &disp_te_default>;

				s6e3fc3_a53x_power_ctrl: s6e3fc3_a53x_power_ctrl {

					actions {

						fc3_a53x_vci_on: vci-on {
							type = <3>;
							reg = <&ddi_vci>;
						};

						fc3_a53x_vdd3_on: vdd3-on {
							type = <3>;
							reg = <&ddi_vdd3>;
						};

						fc3_a53x_vci_off: vci-off {
							type = <4>;
							reg = <&ddi_vci>;
						};

						fc3_a53x_vdd3_off: vdd3-off {
							type = <4>;
							reg = <&ddi_vdd3>;
						};

						fc3_a53x_delay_1ms: delay-1ms {
							type = <1>;
							value = <1>;
						};

						fc3_a53x_delay_10ms: delay-10ms {
							type = <1>;
							value = <10>;
						};

						fc3_a53x_reset_high: reset-high {
							type = <7>;
							gpio = <&disp_reset>;
						};

						fc3_a53x_reset_low: reset-low {
							type = <8>;
							gpio = <&disp_reset>;
						};
					};

					sequences {
						panel_boot_on = <&fc3_a53x_vci_on &fc3_a53x_vdd3_on>;
						panel_power_on = <
							&fc3_a53x_vci_on &fc3_a53x_vdd3_on
							&fc3_a53x_delay_10ms
							&fc3_a53x_reset_high &fc3_a53x_delay_10ms
						>;
						panel_power_off = <
							&fc3_a53x_reset_low &fc3_a53x_delay_1ms
							&fc3_a53x_vci_off &fc3_a53x_delay_10ms
							&fc3_a53x_vdd3_off
						>;
					};
				};

				panels {

					s6e3fc3_a53x: s6e3fc3_a53x {
						ddi = <&s6e3fc3>;
						ap-vendor-setting = <&s6e3fc3>;
						display-mode = <&a53x_panel_display_modes>;
						power-ctrl = <&s6e3fc3_a53x_power_ctrl>;
						freq-hop = <&a53x_freq_hop_table>;
						dqe-suffix = "s6e3fc3_a53x";
						id-mask = <0x00 0x00>;
					};
				};

				panel-lut {
					panel_0 = <&s6e3fc3_a53x>;
				};

				gpios {

					disp_reset: disp-reset {
						gpios = <&gpc7 0 1>; /* ACTIVE_LOW */
						dir = <0>; /* OUT */
						irq-type = <0x0>; /* NONE */
					};

					disp_det: disp-det {
						gpios = <&gpp2 6 1>; /* 0:OK, 1:NOK(active) */
						dir = <1>; /* IN */
						irq-type = <0x2>; /* FALLING EDGE */

						irq-pend {
							reg = <0x0 0x15850A34 0x0>;
							bit = <0x2>;
						};
					};

					conn_det: conn-det {
						gpios = <&gpa0 2 0>;
						dir = <1>;
						irq-type = <0x00002001>; //RISING EDGE | ONE_SHOT
					};

					pcd: pcd {
						gpios = <&gpa0 4 1>; /* 0:NOK(active) 1:OK */
						dir = <1>; /* IN */
						irq-type = <0x2>; /* FALLING EDGE */
					};

					disp_te: disp-te {
						gpios = <&gpg0 1 0>; /* 0:NOK(active) 1:OK */
						dir = <1>; /* IN */
						irq-type = <0x0>; /* NONE */
					};
				};

				regulators {

					ddi_vci: ddi-vci {
						regulator = <&s_l27_reg>;
						type = <1>;
						def-voltage = <3000000>;
					};

					ddi_vdd3: ddi-vdd3 {
						regulator = <&l23_reg>;
						type = <1>;
						def-voltage = <1800000>;
					};
				};
			};
		};
	};
};

&dsim_modes {

	dsim-modes {

		1080x2400@120hs {
			mode-name = "1080x2400@120hs";
			pmsk = <2 0xaa 2 0x7627 0xd 4 0 0 0 0 0 0 0 0>;
			hs-clk = <0x454>;
			esc-clk = <0x14>;
			cmd_underrun_cnt = <0x83b>;
		};

		1080x2400@60phs {
			mode-name = "1080x2400@60phs";
			pmsk = <2 0xaa 2 0x7627 0xd 4 0 0 0 0 0 0 0 0>;
			hs-clk = <0x454>;
			esc-clk = <0x14>;
			cmd_underrun_cnt = <0x83b>;
		};

		1080x2400@30ns {
			mode-name = "1080x2400@30ns";
			pmsk = <2 0xaa 2 0x7627 0xd 4 0 0 0 0 0 0 0 0>;
			hs-clk = <0x454>;
			esc-clk = <0x14>;
			cmd_underrun_cnt = <0x4c2f>;
		};
	};
};

/ {
	fragment@panel_display_mode {
		target-path = "/";

		__overlay__ {

			a53x_panel_display_modes: a53x_panel_display_modes {
				native-mode = <&a53x_panel_display_mode_1080x2400_120hs>;
				exposed-mode = <&a53x_panel_display_mode_1080x2400_120hs &a53x_panel_display_mode_1080x2400_60phs &a53x_panel_display_mode_1080x2400_30ns>;

				a53x_panel_display_mode_1080x2400_120hs: a53x_panel_display_mode_1080x2400_120hs {
					id = "1080x2400_120HS";
					width = <0x438>;
					height = <0x960>;
					refresh_rate = <0x78>;
					refresh_mode = <1>;
					panel_refresh_rate = <0x78>;
					panel_refresh_mode = <1>;
					panel_te_st = <0>;
					panel_te_ed = <0>;
					panel_te_sw_skip_count = <0>;
					panel_te_hw_skip_count = <0>;
					panel_h_porch = <0 0 0>;
					panel_v_porch = <0x10 0 0>;
					dsc_en = <1>;
					dsc_cnt = <1>;
					dsc_slice_num = <2>;
					dsc_slice_w = <0x21c>;
					dsc_slice_h = <0x28>;
					cmd_lp_ref = <0x83b>;
				};

				a53x_panel_display_mode_1080x2400_60phs: a53x_panel_display_mode_1080x2400_60phs {
					id = "1080x2400_60HS_120HS_TE_HW_SKIP_1";
					width = <0x438>;
					height = <0x960>;
					refresh_rate = <0x3c>;
					refresh_mode = <2>;
					panel_refresh_rate = <0x78>;
					panel_refresh_mode = <1>;
					panel_te_st = <0>;
					panel_te_ed = <0>;
					panel_te_sw_skip_count = <0>;
					panel_te_hw_skip_count = <1>;
					panel_h_porch = <0 0 0>;
					panel_v_porch = <0x10 0 0>;
					dsc_en = <1>;
					dsc_cnt = <1>;
					dsc_slice_num = <2>;
					dsc_slice_w = <0x21c>;
					dsc_slice_h = <0x28>;
					cmd_lp_ref = <0x83b>;
				};

				a53x_panel_display_mode_1080x2400_30ns: a53x_panel_display_mode_1080x2400_30ns {
					id = "1080x2400_30NS";
					width = <0x438>;
					height = <0x960>;
					refresh_rate = <0x1e>;
					refresh_mode = <0>;
					panel_refresh_rate = <0x1e>;
					panel_refresh_mode = <0>;
					panel_te_st = <0>;
					panel_te_ed = <0>;
					panel_te_sw_skip_count = <0>;
					panel_te_hw_skip_count = <0>;
					panel_h_porch = <0 0 0>;
					panel_v_porch = <0x10 0 0>;
					dsc_en = <1>;
					dsc_cnt = <1>;
					dsc_slice_num = <2>;
					dsc_slice_w = <0x21c>;
					dsc_slice_h = <0x28>;
					cmd_lp_ref = <0x4c2f>;
				};
			};
		};
	};
};

#include "../s5e8825_samsung_debug.dtsi"

&hsi2c_5 {
	status = "okay";

	sm5451_charger: sm5451@63 {
		compatible = "siliconmitus,sm5451";
		reg = <0x63>;
		sm5451,freq_byp = <1>;
	};
};

/* #include "../s2mf301.dtsi" */
/* From s2mf301.py */
&pinctrl_0 {

	if_pmic_irq: if_pmic_irq {
		samsung,pins = "gpa0-5";
		samsung,pin-function = <0x0>;
		samsung,pin-pud = <0>;
		samsung,pin-drv = <0x0>;
	};
};

&pinctrl_0 {

	usbpd_irq: usbpd_irq {
		samsung,pins = "gpa0-6";
		samsung,pin-function = <0xf>;
		samsung,pin-pud = <0>;
		samsung,pin-drv = <0x2>;
	};
};

&hsi2c_5 {
	#address-cells = <1>;
	#size-cells = <0>;
	status = "okay";
	clock-frequency = <400000>;
	samsung,i2c-max-bus-freq = <400000>;

	sm5714@49 {
		status = "okay";
		compatible = "siliconmitus,sm5714mfd";
		reg = <0x49>;
		pinctrl-names = "default";
		pinctrl-0 = <&if_pmic_irq>;
		sm5714,irq-gpio = <&gpa0 5 0>;
		sm5714,wakeup;
	};
};

&hsi2c_10 {
	i2c-gpio,delay-us = <5>;
	#address-cells = <1>;
	#size-cells = <0>;
	status = "okay";
	clock-frequency = <400000>;
	samsung,i2c-max-bus-freq = <0x61a80>;

	usbpd-sm5714@33 {
		status = "okay";
		compatible = "sm5714-usbpd";
		reg = <0x33>;
		pinctrl-names = "default";
		pinctrl-0 = <&usbpd_irq>;
		usbpd,usbpd_int = <&gpa0 6 0>;
		support_pd_role_swap;

		pdic-manager {
			pdic,max_power = <0x1388>;
			pdic_op_power = <0x9c4>;
			pdic_max_voltage = <0x1770>;
			pdic_max_current = <0x7d0>;
			pdic,min_current = <0x1f4>;
			pdic,giveback = <0>;
			pdic,usb_com_capable = <1>;
			pdic,no_usb_suspend = <1>;
			source,max_voltage = <0x1388>;
			source,min_voltage = <0xfa0>;
			source,max_power = <0x9c4>;
		};
	};
};

/* /home/dpi/qb5_8814/workspace/P4_1716/kernel/kmodule/mfd/VINCE/slsi/s2mf301/s2mf301.a26xs.dtsi */
&hsi2c5_bus {
	samsung,pin-con-pdn = <3>;
	samsung,pin-pud-pdn = <0>;
};

&hsi2c10_bus {
	samsung,pin-pud-pdn = <3>;
};

&pinctrl_0 {

	hall_irq: hall_irq {
		samsung,pins = "gpa0-1";
		samsung,pin-function = <0xf>;
		samsung,pin-pud = <3>;
		samsung,pin-drv = <0>;
	};
};

&pinctrl_0 {

	certify_hall_irq: certify_hall_irq {
		samsung,pins = "gpa0-0";
		samsung,pin-function = <0xf>;
		samsung,pin-pud = <3>;
		samsung,pin-drv = <0>;
	};
};

/* #include "../pmic_S2MPU14.dtsi" */
/* From pmic_S2MPU14.py */
&acpm_mfd_bus1 {
	status = "okay";
	#address-cells = <1>;
	#size-cells = <0>;

	s2mpu14mfd@1f {
		compatible = "samsung,s2mpu14mfd";
		acpm-ipc-channel = <2>;
		s2mpu14,wakeup = "enabled";
		reg = <0x2f>;
		wtsr_en = <1>; /* 1 : enable , 0 : disable */
		/* SEL_VGPIO0S~18S (CONTROL_SEL#) */
		sel_vgpio = <0x0A 0x68 0xB1 0x33 0x03 0x68 0xA1 0x21 0x73 0x33
			0x53 0x56 0xC5 0x7C 0x77 0x33 0x33 0x33 0x03>;

		s2mpu14_gpio: s2mpu14-gpio {
			gpio-controller;
			#gpio-cells = <2>;
			samsung,npins = <4>;
			status = "okay";

			ese_check_default: ese_check_default {
				pins = "gpio_s6";
				pmic-gpio,input-enable;
				pmic-gpio,pull-disable;
				pmic-gpio,drive-strength = <2>;
				samsung,pin-con-pdn = <2>;
				samsung,pin-pud-pdn = <0>;
			};
		};

		regulators {

			s_b1_reg: BUCK1 {
				regulator-name = "vdd_npu";
				regulator-min-microvolt = <400000>;
				regulator-max-microvolt = <1300000>;
				regulator-always-on;
				regulator-ramp-delay = <6000>;
				regulator-initial-mode = <1>; /* V_PWREN_NPU */
			};

			s_b2_reg: BUCK2 {
				regulator-name = "vdd_cpucl0";
				regulator-min-microvolt = <400000>;
				regulator-max-microvolt = <1300000>;
				regulator-always-on;
				regulator-ramp-delay = <6000>;
				regulator-initial-mode = <1>; /* V_PWREN_CPUCL0 */
			};

			s_b3_reg: BUCK3 {
				regulator-name = "vdd_cpucl1";
				regulator-min-microvolt = <400000>;
				regulator-max-microvolt = <1300000>;
				regulator-always-on;
				regulator-ramp-delay = <6000>;
				regulator-initial-mode = <1>; /* V_PWREN_CPUCL1 */
			};

			/*
						s_b4_reg: BUCK4 {
							regulator-name = "vdd_gnss";
							regulator-min-microvolt = <400000>;
							regulator-max-microvolt = <1300000>;
							regulator-always-on;
							regulator-ramp-delay = <6000>;
							regulator-initial-mode = <3>;
						};

			 */
			s_b5_reg: BUCK5 {
				regulator-name = "vdd_mif";
				regulator-min-microvolt = <400000>;
				regulator-max-microvolt = <1300000>;
				regulator-always-on;
				regulator-ramp-delay = <6000>;
				regulator-initial-mode = <1>; /* V_PWREN_MIF */
			};

			s_b6_reg: BUCK6 {
				regulator-name = "vdd_cam";
				regulator-min-microvolt = <400000>;
				regulator-max-microvolt = <1300000>;
				regulator-always-on;
				regulator-ramp-delay = <6000>;
				regulator-initial-mode = <1>; /* V_PWREN_CAM */
			};

			s_b7_reg: BUCK7 {
				regulator-name = "vdd_lldo1s";
				regulator-min-microvolt = <400000>;
				regulator-max-microvolt = <1400000>;
				regulator-always-on;
				regulator-ramp-delay = <6000>;
				regulator-initial-mode = <3>;
			};

			s_b8_reg: BUCK8 {
				regulator-name = "vdd_lldo2s";
				regulator-min-microvolt = <400000>;
				regulator-max-microvolt = <1400000>;
				regulator-always-on;
				regulator-ramp-delay = <6000>;
				regulator-initial-mode = <3>;
			};

			s_bb_reg: BUCKB {
				regulator-name = "vdd_hldo";
				regulator-min-microvolt = <3000000>;
				regulator-max-microvolt = <3600000>;
				regulator-always-on;
				regulator-ramp-delay = <6000>;
				regulator-initial-mode = <3>;
			};

			s_l1_reg: LDO1 {
				regulator-name = "vdd_ldo1s";
				regulator-min-microvolt = <400000>;
				regulator-max-microvolt = <1300000>;
				regulator-ramp-delay = <12000>;
				regulator-initial-mode = <1>;
				regulator-always-on;
			};

			s_l2_reg: LDO2 {
				regulator-name = "vdd_ldo2s";
				regulator-min-microvolt = <400000>;
				regulator-max-microvolt = <1300000>;
				regulator-ramp-delay = <12000>;
				regulator-initial-mode = <1>;
				regulator-always-on;
			};

			/*
						s_l3_reg: LDO3 {
							regulator-name = "${LDO3_name}";
							regulator-min-microvolt = <${LDO3_Vmin}>;
							regulator-max-microvolt = <${LDO3_Vmax}>;
							${LDO3_opt_properties}
							${LDO3_basic_properties}
						};
			 */
			s_l4_reg: LDO4 {
				regulator-name = "vdd_ldo4s";
				regulator-min-microvolt = <400000>;
				regulator-max-microvolt = <1300000>;
				regulator-ramp-delay = <12000>;
				regulator-initial-mode = <1>;
				regulator-always-on;
			};

			s_l5_reg: LDO5 {
				regulator-name = "vdd_ldo5s";
				regulator-min-microvolt = <400000>;
				regulator-max-microvolt = <1300000>;
				regulator-ramp-delay = <12000>;
				regulator-initial-mode = <1>;
				regulator-always-on;
			};

			s_l6_reg: LDO6 {
				regulator-name = "vdd_ldo6s";
				regulator-min-microvolt = <725000>;
				regulator-max-microvolt = <1300000>;
				regulator-ramp-delay = <12000>;
				regulator-initial-mode = <1>;
				regulator-always-on;
			};

			/*
						s_l7_reg: LDO7 {
							regulator-name = "${LDO7_name}";
							regulator-min-microvolt = <${LDO7_Vmin}>;
							regulator-max-microvolt = <${LDO7_Vmax}>;
							${LDO7_opt_properties}
							${LDO7_basic_properties}
						};
			 */
			s_l8_reg: LDO8 {
				regulator-name = "vdd_ldo8s";
				regulator-min-microvolt = <1800000>;
				regulator-max-microvolt = <3375000>;
				regulator-ramp-delay = <12000>;
				regulator-initial-mode = <3>;
				regulator-always-on;
			};

			/*
						s_l9_reg: LDO9 {
							regulator-name = "${LDO9_name}";
							regulator-min-microvolt = <${LDO9_Vmin}>;
							regulator-max-microvolt = <${LDO9_Vmax}>;
							${LDO9_opt_properties}
							${LDO9_basic_properties}
						};

						s_l10_reg: LDO10 {
							regulator-name = "${LDO10_name}";
							regulator-min-microvolt = <${LDO10_Vmin}>;
							regulator-max-microvolt = <${LDO10_Vmax}>;
							${LDO10_opt_properties}
							${LDO10_basic_properties}
						};

						s_l11_reg: LDO11 {
							regulator-name = "${LDO11_name}";
							regulator-min-microvolt = <${LDO11_Vmin}>;
							regulator-max-microvolt = <${LDO11_Vmax}>;
							${LDO11_opt_properties}
							${LDO11_basic_properties}
						};
			 */
			s_l12_reg: LDO12 {
				regulator-name = "vqmmc";
				regulator-min-microvolt = <1800000>;
				regulator-max-microvolt = <2950000>;
				regulator-ramp-delay = <12000>;
				regulator-initial-mode = <3>;
			};

			/*
						s_l13_reg: LDO13 {
							regulator-name = "${LDO13_name}";
							regulator-min-microvolt = <${LDO13_Vmin}>;
							regulator-max-microvolt = <${LDO13_Vmax}>;
							${LDO13_opt_properties}
							${LDO13_basic_properties}
						};

						s_l14_reg: LDO14 {
							regulator-name = "${LDO14_name}";
							regulator-min-microvolt = <${LDO14_Vmin}>;
							regulator-max-microvolt = <${LDO14_Vmax}>;
							${LDO14_opt_properties}
							${LDO14_basic_properties}
						};

						s_l15_reg: LDO15 {
							regulator-name = "${LDO15_name}";
							regulator-min-microvolt = <${LDO15_Vmin}>;
							regulator-max-microvolt = <${LDO15_Vmax}>;
							${LDO15_opt_properties}
							${LDO15_basic_properties}
						};
			 */
			s_l16_reg: LDO16 {
				regulator-name = "vdd_ldo16s";
				regulator-min-microvolt = <3000000>;
				regulator-max-microvolt = <3000000>;
				regulator-ramp-delay = <0x2ee0>;
				regulator-initial-mode = <3>;
				regulator-boot-on;
			};

			s_l17_reg: LDO17 {
				regulator-name = "vdd_ldo17s";
				regulator-min-microvolt = <725000>;
				regulator-max-microvolt = <1300000>;
				regulator-ramp-delay = <12000>;
				regulator-initial-mode = <3>;
			};

			s_l18_reg: LDO18 {
				regulator-name = "vdd_ldo18s";
				regulator-min-microvolt = <725000>;
				regulator-max-microvolt = <1300000>;
				regulator-ramp-delay = <12000>;
				regulator-initial-mode = <3>;
			};

			/*
						s_l19_reg: LDO19 {
							regulator-name = "${LDO19_name}";
							regulator-min-microvolt = <${LDO19_Vmin}>;
							regulator-max-microvolt = <${LDO19_Vmax}>;
							${LDO19_opt_properties}
							${LDO19_basic_properties}
						};

						s_l20_reg: LDO20 {
							regulator-name = "${LDO20_name}";
							regulator-min-microvolt = <${LDO20_Vmin}>;
							regulator-max-microvolt = <${LDO20_Vmax}>;
							${LDO20_opt_properties}
							${LDO20_basic_properties}
						};
			 */
			s_l21_reg: LDO21 {
				regulator-name = "VDD_MOTOR_3P3";
				regulator-min-microvolt = <3300000>;
				regulator-max-microvolt = <3300000>;
				regulator-ramp-delay = <12000>;
				regulator-initial-mode = <3>;
			};

			s_l22_reg: LDO22 {
				regulator-name = "vdd_ldo22s";
				regulator-min-microvolt = <725000>;
				regulator-max-microvolt = <1300000>;
				regulator-ramp-delay = <12000>;
				regulator-initial-mode = <3>;
			};

			s_l23_reg: LDO23 {
				regulator-name = "vdd_ldo23s";
				regulator-min-microvolt = <1100000>;
				regulator-max-microvolt = <1200000>;
				regulator-ramp-delay = <12000>;
				regulator-initial-mode = <3>;
			};

			s_l24_reg: LDO24 {
				regulator-name = "vdd_ldo24s";
				regulator-min-microvolt = <1800000>;
				regulator-max-microvolt = <3375000>;
				regulator-ramp-delay = <12000>;
				regulator-initial-mode = <3>;
			};

			s_l25_reg: LDO25 {
				regulator-name = "vmmc";
				regulator-min-microvolt = <1800000>;
				regulator-max-microvolt = <2950000>;
				regulator-ramp-delay = <12000>;
				regulator-initial-mode = <3>;
			};

			s_l26_reg: LDO26 {
				regulator-name = "VDD_GRIP_3P3";
				regulator-min-microvolt = <3300000>;
				regulator-max-microvolt = <3300000>;
				regulator-ramp-delay = <0x2ee0>;
				regulator-initial-mode = <3>;
			};

			s_l27_reg: LDO27 {
				regulator-name = "vdd_ldo27s";
				regulator-min-microvolt = <3000000>;
				regulator-max-microvolt = <3000000>;
				regulator-initial-mode = <3>;
				regulator-boot-on;
			};
		}; /* end of regulators */
	}; /* end of s2mpu14mfd@1f */
}; /* end of acpm_mfd_bus0 */

&hsi2c_13 {
	gpios = <&gpp3 3 0 &gpp3 2 0>;
	pinctrl-0 = <&grip_i2c_sda
				&grip_i2c_scl
	#if 0
				&grip_ldo_en
	#endif
				>;
	#address-cells = <1>;
	#size-cells = <0>;
	status = "okay";
	clock-frequency = <400000>;
	pinctrl-names = "default";

	sx938x: sx938x-i2c@28 {
		compatible = "sx938x";
		reg = <0x28>;
		status = "okay";
		pinctrl-names = "default";
		pinctrl-0 = <&grip_int>;
		interrupt-parent = <&gpa1>;
		interrupts = <3 0 0>;
		sx938x,dvdd_vreg_name = "VDD_GRIP_3P3";
		sx938x,nirq-gpio = <&gpa1 3 0>;
		Semtech,reg-num = <0x18>;
		sx938x,irq_enable_reg = <0xe>;
		sx938x,irqcfg_reg = <0>;
		sx938x,gnrl_ctrl0_reg = <3>;
		sx938x,gnrl_ctrl1_reg = <0>;
		sx938x,gnrl_ctrl2_reg = <0x19>;
		sx938x,afe_ctrl1_reg = <1>;
		sx938x,afe_param0_phr_reg = <0xc>;
		sx938x,afe_param1_phr_reg = <0x46>;
		sx938x,afe_param0_phm_reg = <0xf>;
		sx938x,afe_param1_phm_reg = <0x26>;
		sx938x,proxctrl0_phr_reg = <9>;
		sx938x,proxctrl0_phm_reg = <0xa>;
		sx938x,proxctrl1_reg = <0x20>;
		sx938x,proxctrl2_reg = <0x60>;
		sx938x,proxctrl3_reg = <0xd>;
		sx938x,proxctrl4_reg = <0x15>;
		sx938x,proxctrl5_reg = <0x12>;
		sx938x,refcorr0_reg = <0>;
		sx938x,refcorr1_reg = <0>;
		sx938x,usefilter0_reg = <0>;
		sx938x,usefilter1_reg = <0>;
		sx938x,usefilter2_reg = <0>;
		sx938x,usefilter3_reg = <0>;
		sx938x,usefilter4_reg = <0>;
	};
};

/* #include "../sensors_isg6320.dtsi" */
/* From sensors_isg6320.py */
&pinctrl_6 {

	grip_i2c_sda: grip-i2c-sda {
		samsung,pins = "gpp3-3";
		samsung,pin-function = <0x3>;
		samsung,pin-pud = <3>;
		samsung,pin-drv = <0x0>;
		samsung,pin-pud-pdn = <0>;
	};

	grip_i2c_scl: grip-i2c-scl {
		/* /home/dpi/qb5_8814/workspace/P4_1716/kernel/kmodule/sensors/isg6320/dts/isg6320_hwparam.a26xs.dtsi */
		samsung,pins = "gpp3-2";
		samsung,pin-function = <0x3>;
		samsung,pin-pud = <3>;
		samsung,pin-drv = <0x0>;
		samsung,pin-pud-pdn = <0>;
	};
};

&pinctrl_0 {

	grip_int: grip-int {
		samsung,pins = "gpa1-3";
		samsung,pin-function = <0xf>;
		samsung,pin-pud = <0>;
		samsung,pin-drv = <0x0>;
	};
};

/* #include "../pmic_S2MPU13.dtsi" */
/* From pmic_S2MPU13.py */
&pinctrl_0 {

	pm_wrstbi: pm-wrstbi {
		samsung,pins = "gpc1-0";
		samsung,pin-con-pdn = <3>;
		samsung,pin-pud-pdn = <0>;
	};
};

&pinctrl_6 {

	smpl_warn: smpl-warn {
		samsung,pins = "gpg0-0";
		samsung,pin-function = <15>;
		samsung,pin-pud = <0>;
		samsung,pin-drv = <0>;
		samsung,pin-con-pdn = <2>;
		samsung,pin-pud-pdn = <0>;
	};
};

&acpm_mfd_bus0 {
	status = "okay";
	#address-cells = <1>;
	#size-cells = <0>;

	s2mpu13mfd@1f {
		compatible = "samsung,s2mpu13mfd";
		acpm-ipc-channel = <2>;
		s2mpu13,wakeup = "enabled";
		reg = <0x1f>;
		interrupts = <0 24 4>;
		interrupt-parent = <&gic>;
		pinctrl-names = "default";
		pinctrl-0 = <&pm_wrstbi &smpl_warn>;
		gpios = <&gpg0 0 0>;
		/* RTC: wtsr/smpl */
		wtsr_en = "enabled"; /* enable */
		smpl_en = "enabled"; /* enable */
		wtsr_timer_val = <3>; /* 1000ms */
		smpl_timer_val = <0>; /* 100ms */
		sub_smpl_en = "enabled"; /* enable */
		check_jigon = <0>; /* do not check jigon */
		/* RTC: If it's first boot, reset rtc to 1/1/2021 12:00:00(Wed) */
		init_time,sec = <0>;
		init_time,min = <0>;
		init_time,hour = <12>;
		init_time,mday = <1>;
		init_time,mon = <0>;
		init_time,year = <121>;
		init_time,wday = <5>;
		/* SMPL_WARN */
		smpl_warn_en = <1>; /* 1 : enable , 0 : disable */
		/* SEL_VGPIO0M~18M (CONTROL_SEL#) */
		sel_vgpio = <0x24 0x32 0x11 0x39 0x33 0x33 0x22 0x33 0x24 0xB1
			0xC1 0xB1 0x77 0x5B 0x5E 0xCC 0x73 0x33 0xF3>;

		s2mpu13_gpadc: s2mpu13-gpadc {
			#io-channel-cells = <1>;
			io-channel-ranges;
			acpm-ipc-channel = <10>;
		};

		s2mpu13_gpio: s2mpu13-gpio {
			gpio-controller;
			#gpio-cells = <2>;
			samsung,npins = <5>;
			status = "okay";
		};

		s2mpu13-keys {

			button@1 {
				label = "pmic-keys: KEY_POWER";
				linux,code = <116>;
				wakeup = <1>;
			};
		};

		regulators {

			b1_reg: BUCK1 {
				regulator-name = "vdd_g3d";
				regulator-min-microvolt = <400000>;
				regulator-max-microvolt = <1300000>;
				regulator-always-on;
				regulator-ramp-delay = <6000>;
				regulator-initial-mode = <1>; /* V_PWREN_G3D */
			};

			/*
						b2_reg: BUCK2 {
							regulator-name = "vdd_cpu_cp";
							regulator-min-microvolt = <400000>;
							regulator-max-microvolt = <1300000>;
							regulator-always-on;
							regulator-ramp-delay = <6000>;
							regulator-initial-mode = <3>;
						};

						b3_reg: BUCK3 {
							regulator-name = "vdd_cp";
							regulator-min-microvolt = <400000>;
							regulator-max-microvolt = <1300000>;
							regulator-always-on;
							regulator-ramp-delay = <6000>;
							regulator-initial-mode = <3>;
						};
			 */
			b4_reg: BUCK4 {
				regulator-name = "vdd_mem_vdd2";
				regulator-min-microvolt = <400000>;
				regulator-max-microvolt = <1300000>;
				regulator-always-on;
				regulator-ramp-delay = <6000>;
				regulator-initial-mode = <3>; /* V_PWREN_MIF */
			};

			b5_reg: BUCK5 {
				regulator-name = "vdd2_int";
				regulator-min-microvolt = <400000>;
				regulator-max-microvolt = <1300000>;
				regulator-always-on;
				regulator-ramp-delay = <6000>;
				regulator-initial-mode = <1>; /* V_PWREN_MIF */
			};

			b6_reg: BUCK6 {
				regulator-name = "vddq_mem_vddq";
				regulator-min-microvolt = <400000>;
				regulator-max-microvolt = <1300000>;
				regulator-always-on;
				regulator-ramp-delay = <6000>;
				regulator-initial-mode = <1>; /* V_PWREN_MIF */
			};

			/*
						b7_reg: BUCK7 {
							regulator-name = "vdd_wlbt";
							regulator-min-microvolt = <400000>;
							regulator-max-microvolt = <1300000>;
							regulator-always-on;
							regulator-ramp-delay = <6000>;
							regulator-initial-mode = <3>;
						};
			 */
			b8_reg: BUCK8 {
				regulator-name = "vdd_lldo1";
				regulator-min-microvolt = <400000>;
				regulator-max-microvolt = <1400000>;
				regulator-always-on;
				regulator-ramp-delay = <6000>;
				regulator-initial-mode = <3>;
			};

			b9_reg: BUCK9 {
				regulator-name = "vdd_lldo2";
				regulator-min-microvolt = <900000>;
				regulator-max-microvolt = <1400000>;
				regulator-always-on;
				regulator-ramp-delay = <6000>;
				regulator-initial-mode = <3>;
			};

			b10_reg: BUCK10 {
				regulator-name = "vdd_mldo";
				regulator-min-microvolt = <1750000>;
				regulator-max-microvolt = <2150000>;
				regulator-always-on;
				regulator-ramp-delay = <6000>;
				regulator-initial-mode = <3>;
			};

			l1_reg: LDO1 {
				regulator-name = "vdd_ldo1";
				regulator-min-microvolt = <725000>;
				regulator-max-microvolt = <1300000>;
				regulator-ramp-delay = <12000>;
				regulator-initial-mode = <3>;
				regulator-always-on;
			};

			l2_reg: LDO2 {
				regulator-name = "vdd_ldo2";
				regulator-min-microvolt = <1600000>;
				regulator-max-microvolt = <1950000>;
				regulator-ramp-delay = <12000>;
				regulator-initial-mode = <3>;
				regulator-always-on;
			};

			/*
						l3_reg: LDO3 {
							regulator-name = "${LDO3_name}";
							regulator-min-microvolt = <${LDO3_Vmin}>;
							regulator-max-microvolt = <${LDO3_Vmax}>;
							${LDO3_opt_properties}
							${LDO3_basic_properties}
						};

						l4_reg: LDO4 {
							regulator-name = "${LDO4_name}";
							regulator-min-microvolt = <${LDO4_Vmin}>;
							regulator-max-microvolt = <${LDO4_Vmax}>;
							${LDO4_opt_properties}
							${LDO4_basic_properties}
						};

						l5_reg: LDO5 {
							regulator-name = "${LDO5_name}";
							regulator-min-microvolt = <${LDO5_Vmin}>;
							regulator-max-microvolt = <${LDO5_Vmax}>;
							${LDO5_opt_properties}
							${LDO5_basic_properties}
						};

						l6_reg: LDO6 {
							regulator-name = "${LDO6_name}";
							regulator-min-microvolt = <${LDO6_Vmin}>;
							regulator-max-microvolt = <${LDO6_Vmax}>;
							${LDO6_opt_properties}
							${LDO6_basic_properties}
						};
			 */
			l7_reg: LDO7 {
				regulator-name = "vdd_ldo7";
				regulator-min-microvolt = <400000>;
				regulator-max-microvolt = <1300000>;
				regulator-ramp-delay = <12000>;
				regulator-initial-mode = <1>;
				regulator-always-on;
			};

			/*
						l8_reg: LDO8 {
							regulator-name = "${LDO8_name}";
							regulator-min-microvolt = <${LDO8_Vmin}>;
							regulator-max-microvolt = <${LDO8_Vmax}>;
							${LDO8_opt_properties}
							${LDO8_basic_properties}
						};
			 */
			l9_reg: LDO9 {
				regulator-name = "vdd_ldo9";
				regulator-min-microvolt = <400000>;
				regulator-max-microvolt = <1300000>;
				regulator-ramp-delay = <12000>;
				regulator-initial-mode = <1>;
				regulator-always-on;
			};

			l10_reg: LDO10 {
				regulator-name = "vdd_ldo10";
				regulator-min-microvolt = <400000>;
				regulator-max-microvolt = <1300000>;
				regulator-ramp-delay = <12000>;
				regulator-initial-mode = <1>;
				regulator-always-on;
			};

			l11_reg: LDO11 {
				regulator-name = "vdd_ldo11";
				regulator-min-microvolt = <725000>;
				regulator-max-microvolt = <1300000>;
				regulator-ramp-delay = <12000>;
				regulator-initial-mode = <1>;
				regulator-always-on;
			};

			l12_reg: LDO12 {
				regulator-name = "vdd_ldo12";
				regulator-min-microvolt = <725000>;
				regulator-max-microvolt = <1300000>;
				regulator-ramp-delay = <12000>;
				regulator-initial-mode = <3>;
			};

			l13_reg: LDO13 {
				regulator-name = "vdd_ldo13";
				regulator-min-microvolt = <1600000>;
				regulator-max-microvolt = <1950000>;
				regulator-ramp-delay = <12000>;
				regulator-initial-mode = <1>;
				regulator-always-on;
			};

			l14_reg: LDO14 {
				regulator-name = "vdd_ldo14";
				regulator-min-microvolt = <1800000>;
				regulator-max-microvolt = <1800000>;
				regulator-ramp-delay = <12000>;
				regulator-initial-mode = <1>;
			};

			/*
						l15_reg: LDO15 {
							regulator-name = "${LDO15_name}";
							regulator-min-microvolt = <${LDO15_Vmin}>;
							regulator-max-microvolt = <${LDO15_Vmax}>;
							${LDO15_opt_properties}
							${LDO15_basic_properties}
						};

						l16_reg: LDO16 {
							regulator-name = "${LDO16_name}";
							regulator-min-microvolt = <${LDO16_Vmin}>;
							regulator-max-microvolt = <${LDO16_Vmax}>;
							${LDO16_opt_properties}
							${LDO16_basic_properties}
						};
			 */
			l17_reg: LDO17 {
				regulator-name = "vdd_ldo17";
				regulator-min-microvolt = <850000>;
				regulator-max-microvolt = <850000>;
				regulator-ramp-delay = <12000>;
				regulator-initial-mode = <1>;
			};

			/*
						l18_reg: LDO18 {
							regulator-name = "${LDO18_name}";
							regulator-min-microvolt = <${LDO18_Vmin}>;
							regulator-max-microvolt = <${LDO18_Vmax}>;
							${LDO18_opt_properties}
							${LDO18_basic_properties}
						};

						l19_reg: LDO19 {
							regulator-name = "${LDO19_name}";
							regulator-min-microvolt = <${LDO19_Vmin}>;
							regulator-max-microvolt = <${LDO19_Vmax}>;
							${LDO19_opt_properties}
							${LDO19_basic_properties}
						};

						l20_reg: LDO20 {
							regulator-name = "${LDO20_name}";
							regulator-min-microvolt = <${LDO20_Vmin}>;
							regulator-max-microvolt = <${LDO20_Vmax}>;
							${LDO20_opt_properties}
							${LDO20_basic_properties}
						};
			 */
			l21_reg: LDO21 {
				regulator-name = "vdd_ldo21";
				regulator-min-microvolt = <400000>;
				regulator-max-microvolt = <1300000>;
				regulator-ramp-delay = <12000>;
				regulator-initial-mode = <3>;
			};

			l22_reg: LDO22 {
				regulator-name = "vdd_ldo22";
				regulator-min-microvolt = <1800000>;
				regulator-max-microvolt = <1800000>;
				regulator-ramp-delay = <12000>;
				regulator-initial-mode = <3>;
			};

			l23_reg: LDO23 {
				regulator-name = "vdd_ldo23";
				regulator-min-microvolt = <1800000>;
				regulator-max-microvolt = <1800000>;
				regulator-initial-mode = <3>;
				regulator-boot-on;
			};

			/*
						l24_reg: LDO24 {
							regulator-name = "${LDO24_name}";
							regulator-min-microvolt = <${LDO24_Vmin}>;
							regulator-max-microvolt = <${LDO24_Vmax}>;
							${LDO24_opt_properties}
							${LDO24_basic_properties}
						};
			 */
			l25_reg: LDO25 {
				regulator-name = "nfc_pvdd";
				regulator-min-microvolt = <1800000>;
				regulator-max-microvolt = <1800000>;
				regulator-ramp-delay = <12000>;
				regulator-initial-mode = <3>;
			};

			l26_reg: LDO26 {
				/* /home/dpi/qb5_8814/workspace/P4_1716/kernel/kmodule/battery/suwon/fuelgauge/s2mf301/a26xs/s2mf301_fuelgauge.05.dtsi */
				/* Battery data same as s2mf301_fuelgauge.dtsi*/
				/* #include "../sensorhub_shub.dtsi" */
				/* From sensorhub_shub.py */
				regulator-name = "VDD_SENSOR_1P8";
				regulator-min-microvolt = <1800000>;
				regulator-max-microvolt = <1800000>;
				regulator-ramp-delay = <12000>;
				regulator-initial-mode = <3>;
			};

			l27_reg: LDO27 {
				regulator-name = "vdd_ldo27";
				regulator-min-microvolt = <1600000>;
				regulator-max-microvolt = <1950000>;
				regulator-ramp-delay = <12000>;
				regulator-initial-mode = <3>;
			};
		}; /* end of regulators */
	}; /* end of s2mpu13mfd@1f */
}; /* end of acpm_mfd_bus0 */

&pinctrl_0 {

	gw9558x_rst: gw9558x-rst {
		samsung,pins = "gpc3-0";
		samsung,pin-function = <1>;
		samsung,pin-pud = <1>;
		samsung,pin-drv = <0>;
		samsung,pin-con-pdn = <3>;
		samsung,pin-pud-pdn = <1>;
	};
};

&pinctrl_6 {

	gw9558x_ldo: gw9558x-ldo {
		samsung,pins = "gpp3-4";
		samsung,pin-function = <1>;
		samsung,pin-pud = <1>;
		samsung,pin-drv = <0>;
		samsung,pin-con-pdn = <3>;
		samsung,pin-pud-pdn = <1>;
	};
};

&pinctrl_6 {

	spi_fp_bus_inactive: spi-fp-bus-inactive {
		samsung,pins = "gpp0-7", "gpp0-4", "gpp0-5";
		samsung,pin-function = <1>;
		samsung,pin-pud = <0>;
		samsung,pin-drv = <1>;
		samsung,pin-val = <0>;
	};

	spi_fp_miso_inactive: spi-fp-miso-inactive {
		samsung,pins = "gpp0-6";
		samsung,pin-function = <0>;
		samsung,pin-pud = <1>;
		samsung,pin-drv = <1>;
	};

	spi_fp_clk: spi-fp-clk {
		samsung,pins = "gpp0-4";
		samsung,pin-function = <2>;
		samsung,pin-pud = <1>;
		samsung,pin-drv = <1>;
	};

	spi_fp_cs: spi-fp-cs {
		samsung,pins = "gpp0-7";
		samsung,pin-function = <2>;
		samsung,pin-pud = <3>;
		samsung,pin-drv = <1>;
	};

	spi_fp_miso: spi-fp-miso {
		samsung,pins = "gpp0-6";
		samsung,pin-function = <2>;
		samsung,pin-pud = <1>;
		samsung,pin-drv = <1>;
	};

	spi_fp_mosi: spi-fp-mosi {
		samsung,pins = "gpp0-5";
		samsung,pin-function = <2>;
		samsung,pin-pud = <1>;
		samsung,pin-drv = <1>;
	};
};

/* #include "../regulator-fixe-1.dtsi" */
/* From regulator-fixed.py */
/*
 * This pinctrl code is only for PULL state change.
 * IN-OUT setting is set to OUTPUT at fixed-regulator probe.
 */
&pinctrl_4 {

	ldo_gpio0: ldo_gpio0 {
		samsung,pins = "gpf1-0";
		samsung,pin-function = <0x1>;
		samsung,pin-pud = <0>;
	};
};

/ {
	fragment@model {
		target-path = "/";

		__overlay__ {
			#address-cells = <2>;
			#size-cells = <1>;

			shub {
				pinctrl-names = "default";
				sensor-vdd-regulator = "VDD_SENSOR_1P8";
				compatible = "shub";
				acc-motor-coef = <0>;
				acc-lsm6dsotr-position = <2>;
				mag-ak09918c-position = <7>;
				mag-ak09918c-array = [af 59 e3 02 97 8c ff ba d0 35 c4 53 b3 23 01 77 ff 72 44 00 bf 03 3a 8f 0d fb 1e];
				light-position = <0x19 0x50 3 7 2 0>;
				pressure-sw-offset = <0xffffffbe>;
			};

			sec_reloc_gpio: samsung,reloc_gpio {
				compatible = "samsung,reloc_gpio";
				status = "okay";
				sec,gpio-label = "reloc_gpio";
				sec,reloc-base = <0>;
			};

			gpio_keys {
				status = "okay";
				compatible = "gpio-keys";
				pinctrl-names = "default";
				pinctrl-0 = <&key_voldown &key_volup>;

				button@2 {
					label = "gpio-keys: KEY_VOLUMEDOWN";
					linux,code = <114>;
					gpios = <&gpa0 7 0xf>;
					gpio-key,wakeup;
					debounce-interval = <0xf>;
				};

				button@3 {
					label = "gpio-keys: KEY_VOLUMEUP";
					linux,code = <115>;
					gpios = <&gpa1 0 0xf>;
					gpio-key,wakeup;
					debounce-interval = <0xf>;
				};
			};
		}; /* end of __overlay__ */
	}; /* end of fragment */
};

&pinctrl_0 {

	stm_attn_irq: stm_attn_irq {
		samsung,pins = "gpa0-3";
		samsung,pin-function = <0xf>;
		samsung,pin-pud = <0>;
	};

	stm_attn_input: stm_attn_input {
		samsung,pins = "gpa0-3";
		samsung,pin-function = <0>;
		samsung,pin-pud = <1>;
	};
};

&hsi2c_6 {
	#address-cells = <1>;
	#size-cells = <0>;
	status = "ok";
	samsung,reset-before-trans;

	tsp_stm: touchscreen@49 {
		status = "disabled";
		compatible = "stm,stm_ts";
		reg = <0x49>;
		pinctrl-names = "on_state", "off_state";
		pinctrl-0 = <&stm_attn_irq>;
		pinctrl-1 = <&stm_attn_input>;
		tsp_io_ldo-supply = <&fixed_regulator0>;
		tsp_avdd_ldo-supply = <&s_l16_reg>;
		sec,irq_gpio = <&gpa0 3 0>;
		sec,project_name = "a53x", "";
		sec,bringup = <1>;
		sec,ss_touch_num = <1>;
		sec,tclm_level = <1>;
		sec,area-size = <0x85 0x10a 0x155>;
		sec,max_coords = <0x1000 0x1000>;
		enable_settings_aot;
		support_fod;
		support_fod_lp_mode;
		support_mis_calibration_test;
		support_ear_detect_mode;
		support_open_short_test;
		sec,regulator_boot_on;
	};
};

&pinctrl_6 {

	ese_spi_bus_suspend: ese_spi_bus_suspend {
		samsung,pins = "gpp0-0", "gpp0-1", "gpp0-2";
		samsung,pin-function = <0>;
		samsung,pin-pud = <1>;
		samsung,pin-drv = <0>;
		samsung,pin-con-pdn = <2>;
		samsung,pin-pud-pdn = <1>;
	};

	ese_spi_cs_suspend: ese_spi_cs_suspend {
		samsung,pins = "gpp0-3";
		samsung,pin-function = <1>;
		samsung,pin-pud = <0>;
		samsung,pin-drv = <0>;
		samsung,pin-val = <1>;
		samsung,pin-con-pdn = <1>;
		samsung,pin-pud-pdn = <0>;
	};

	ese_spi_bus: ese_spi_bus {
		samsung,pins = "gpp0-0", "gpp0-1", "gpp0-2";
		samsung,pin-function = <2>;
		samsung,pin-pud = <0>;
		samsung,pin-drv = <0>;
	};

	ese_spi_cs: ese_spi_cs {
		samsung,pins = "gpp0-3";
		samsung,pin-function = <1>;
		samsung,pin-pud = <0>;
		samsung,pin-drv = <0>;
	};
};

&spi_0 {
	status = "ok";
	pinctrl-names = "ese_active", "ese_suspend";
	pinctrl-0 = <&ese_spi_bus &ese_spi_cs>;
	pinctrl-1 = <&ese_spi_bus_suspend &ese_spi_cs_suspend>;

	ese_spi@0 {
		compatible = "ese_p3";
		reg = <0>;
		spi-max-frequency = <0x6acfc0>;
		check_ese = <&s2mpu14_gpio 6 0>;
		pinctrl-names = "default";
		pinctrl-0 = <&ese_check_default>;
		gpio-controller;
		#gpio-cells = <2>;
		ese_p3,cs-gpio = <&gpp0 3 0>;

		controller-data {
			samsung,spi-feedback-delay = <0>;
			samsung,spi-chip-select-mode = <0>;
		};
	};
};

/ {
	fragment@ese_platform {
		target-path = "/";

		__overlay__ {

			ese_platform {
				compatible = "p3_platform";
			};
		};
	};
};

&pinctrl_6 {

	nfc_i2c_bus: nfc_i2c_bus {
		samsung,pins = "gpp1-0", "gpp1-1";
		samsung,pin-function = <2>;
		samsung,pin-pud = <0>;
		samsung,pin-drv = <0>;
		samsung,pin-con-pdn = <2>;
		samsung,pin-pud-pdn = <0>;
	};
};

&pinctrl_0 {

	xclkout: xclkout {
		samsung,pins = "gpq0-3";
		samsung,pin-function = <2>;
		samsung,pin-pud = <0>;
	};

	xclkout_nc: xclkout_nc {
		samsung,pins = "gpq0-3";
		samsung,pin-function = <0>;
		samsung,pin-pud = <1>;
	};
};

&pinctrl_0 {

	nfc_firm: nfc_firm {
		samsung,pins ="gpc5-0";
		samsung,pin-function = <1>;
		samsung,pin-pud = <0>;
		samsung,pin-val = <0>;
		samsung,pin-con-pdn =<3>;
		samsung,pin-pud-pdn = <0>;
	};

	nfc_firm_nc: nfc_firm_nc {
		samsung,pins = "gpc5-0";
		samsung,pin-function = <0>;
		samsung,pin-pud = <1>;
	};
};

&pinctrl_0 {

	nfc_en: nfc_en {
		samsung,pins = "gpc4-0";
		samsung,pin-function = <1>;
		samsung,pin-pud = <0>;
		samsung,pin-val = <1>;
		samsung,pin-con-pdn = <3>;
		samsung,pin-pud-pdn = <0>;
	};

	nfc_en_nc: nfc_en_nc {
		samsung,pins = "gpc4-0";
		samsung,pin-function = <0>;
		samsung,pin-pud = <1>;
	};
};

&pinctrl_0 {

	nfc_clk_req: nfc_clk_req {
		samsung,pins = "gpa1-1";
		samsung,pin-function = <2>;
		samsung,pin-pud = <1>;
	};

	nfc_clk_req_nc: nfc_clk_req_nc {
		samsung,pins = "gpa1-1";
		samsung,pin-function = <0x0>;
		samsung,pin-pud = <1>;
	};
};

&hsi2c_4 {
	#address-cells = <1>;
	#size-cells = <0>;
	status = "okay";
	clock-frequency = <400000>;
	samsung,i2c-max-bus-freq = <0x61a80>;
	samsung,reset-before-trans;
	pinctrl-names = "default";
	pinctrl-0 = <&nfc_i2c_bus>;

	sec_nfc: sec-nfc@27 {
		compatible = "sec-nfc";
		reg = <0x27>;
		interrupts = <2 0 0>;
		interrupt-parent = <&gpa1>;
		sec-nfc,ven-gpio = <&gpc4 0 0>;
		sec-nfc,firm-gpio = <&gpc5 0 0>;
		sec-nfc,irq-gpio = <&gpa1 2 0>;
		sec-nfc,clk_req-gpio = <&gpa1 1 0xf>;
		sec-nfc,coldreset-gpio = <&gpp3 5 0>;
		nfc_pvdd-supply = <&l25_reg>;
		sec-nfc,ldo_control;
		clocks = <&clock ((1600) + 0)>;
		clock-names = "oscclk_nfc";
		sec-nfc,nfc_ap_clk;
		pinctrl-names = "default", "nfc_nc";
		pinctrl-0 = <&nfc_en &nfc_firm &xclkout &nfc_clk_req>;
		pinctrl-1 = <&nfc_en_nc &nfc_firm_nc &xclkout_nc &nfc_clk_req_nc>;
	};
};

/* #include "../display_common_oled_board.dtsi" */
/* From display_common_oled_board.py */
/*
 * Samsung Exynos SoC series Panel driver
 *
 * Copyright (c) 2020 Samsung Electronics Co., Ltd
 *
 * This program is free software; you can redistribute it and/or modify
 * it under the terms of the GNU General Public License version 2 as
 * published by the Free Software Foundation.
 */
&pinctrl_0 {

	disp_rst_default: disp-rst-default {
		samsung,pins = "gpc7-0";
		samsung,pin-function = <1>; // OUT
		samsung,pin-pud = <0>; // NP
		samsung,pin-con-pdn = <3>; // PREV in sleep
		samsung,pin-pud-pdn = <0>; // NP in sleep
	};
};

&pinctrl_6 {

	disp_det_default: disp_det_default {
		samsung,pins = "gpp2-6";
		samsung,pin-function = <0x0>;
		samsung,pin-pud = <1>;
	};
};

&pinctrl_0 {

	conn_det_default: conn_det_default {
		samsung,pins = "gpa0-2";
		samsung,pin-function = <0>;
		samsung,pin-pud = <0>; // NP
	};
};

&pinctrl_6 {

	disp_te_default: disp_te_default {
		samsung,pins = "gpg0-1";
		samsung,pin-funciton = <0xf>; // INT
		samsung,pin-pud = <1>; // PD
		samsung,pin-con-pdn = <3>; // PREV in sleep
		samsung,pin-pud-pdn = <0>; // NP in sleep
	};
};

&pinctrl_0 {

	pcd_default: pcd_default {
		samsung,pins = "gpa0-4";
		samsung,pin-function = <0x0>;
		samsung,pin-pud = <1>;
	};
};

&pinctrl_0 {

	berlin_attn_irq: berlin_attn_irq {
		samsung,pins = "gpa0-3";
		samsung,pin-function = <0xf>;
		samsung,pin-pud = <0>;
	};

	berlin_attn_irq_suspend: berlin_attn_irq_suspend {
		samsung,pins = "gpa0-3";
		samsung,pin-function = <0>;
		samsung,pin-pud = <0>;
	};
};

&hsi2c_6 {
	#address-cells = <1>;
	#size-cells = <0>;
	status = "okay";

	tsp_goodix: touchscreen@5d {
		status = "okay";
		compatible = "goodix,berlin";
		reg = <0x5d>;
		pinctrl-names = "on_state", "off_state";
		pinctrl-0 = <&berlin_attn_irq>;
		pinctrl-1 = <&berlin_attn_irq_suspend>;
		tsp_avdd_ldo-supply = <&s_l16_reg>;
		sec,irq_gpio = <&gpa0 3 0x00>;
		sec,irq_flag = <0x2002>;
		sec,enable_sysinput_enabled;
		support_open_short_test;
		not_support_io_ldo;
		support_ear_detect_mode;
		support_fod;
		support_fod_lp_mode;
		enable_settings_aot;
		sec,refresh_rate_enable;
		sec,enable_esd_check;
		sec,max_coords = <0x438 0x960>;
		sec,firmware_name = "gt9895_a53x.bin";
		sync-reportrate-120;
		sec,ic_type = <2>;
		sec,max_drv_num = <17>;
		sec,max_sen_num = <35>;
		sec,drv_map = <35 36 37 38 39 40 41 42 43 44 45 46 47 48 49 50 51>;
		sec,sen_map = <0 1 2 3 4 5 6 7 8 9 10 11 12 13 14 15 16 17 18 19 20 21 22 23 24 25 26 27 28 29 30 31 32 33 34>;
		sec,short_test_time_reg = <0x1479e>;
		sec,short_test_status_reg = <0x13400>;
		sec,short_test_result_reg = <0x13408>;
		sec,drv_drv_reg = <0x13446>;
		sec,sen_sen_reg = <0x136ee>;
		sec,drv_sen_reg = <0x14152>;
		sec,diff_code_reg = <0x14734>;
		sec,production_test_addr = <0x15d4c>;
		sec,switch_freq_cmd = <0xb1>;
		sec,switch_cfg_cmd = <0x64>;
		sec,snr_cmd = <0x65>;
		sec,sensitive_cmd = <0x66>;
		sec,isp_ram_reg = <0x23800>;
		sec,flash_cmd_reg = <0x12400>;
		sec,isp_buffer_reg = <0x12410>;
		sec,config_data_reg = <0x3e000>;
		sec,misctl_reg = <0xd804>;
		sec,watch_dog_reg = <0xd040>;
		sec,config_id_reg = <0x10076>;
		sec,enable_misctl_val = " p", "";
	};
};

/* #include "../sensorhub_s5e8825.dtsi" */
/* From sensorhub_s5e8825.py */
&contexthub_0 {
	multi-os = "disabled";
};

#include "s5e8825.a53x_eur_open.05.dtsi"

/ {
	compatible = "SAMSUNG,A53X_EUR_OPEN", "SAMSUNG,EXYNOS8825";
	dtbo-hw_rev = <5>;
	dtbo-hw_rev_end = <5>;
};
